VERSION ""

NS_ :

BS_:

BU_: ECU

BO_ 1706 frame_1706: 8 Vector__XXX
 SG_ checksum_57_8 : 63|8@0+ (1,0) [0|255] ""  ECU
 SG_ sig_2_29 : 2|29@1+ (1e-12,0) [0|0.00053687091] "W"  ECU
 SG_ sig_0_2 : 0|2@1+ (1,0) [0|3] ""  ECU
 SG_ sig_42_14 : 42|14@1- (1,0) [-8192|8190] ""  ECU
 SG_ sig_34_6 : 34|6@1+ (1,0) [0|62] ""  ECU
 SG_ sig_33_2 : 33|2@0- (1,0) [-2|1] ""  ECU

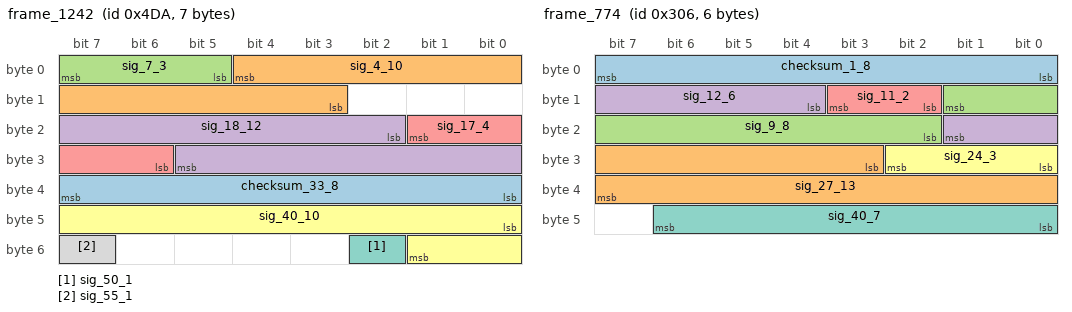
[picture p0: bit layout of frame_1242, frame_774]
BO_ 1242 frame_1242: 7 Vector__XXX
 SG_ checksum_33_8 : 39|8@0+ (1,0) [0|255] ""  ECU
 SG_ sig_4_10 : 4|10@0- (1e-06,0) [-0.000512|0.00051] "V"  ECU
 SG_ sig_7_3 : 7|3@0- (1,0) [-4|2] ""  ECU
 SG_ sig_18_12 : 18|12@1+ (0.001,-3.1622776602) [-3.1622776602|0.93172233983] "s"  ECU
 SG_ sig_17_4 : 17|4@0- (1,0) [-8|6] ""  ECU
 SG_ sig_40_10 : 40|10@1+ (0.0001,0.031622776602) [0.031622776602|0.1338227766] "W"  ECU
 SG_ sig_50_1 : 50|1@1+ (1,0) [0|1] ""  ECU
 SG_ sig_55_1 : 55|1@0+ (1,0) [0|1] ""  ECU

BO_ 774 frame_774: 6 Vector__XXX
 SG_ checksum_1_8 : 7|8@0+ (1,0) [0|255] ""  ECU
 SG_ sig_27_13 : 27|13@1- (0.0001,0) [-0.4096|0.4094] "W"  ECU
 SG_ sig_9_8 : 9|8@0- (1e-05,0) [-0.00128|0.00126] "kWh"  ECU
 SG_ sig_12_6 : 12|6@1- (1,0) [-32|30] ""  ECU
 SG_ sig_11_2 : 11|2@0- (1,0) [-2|1] ""  ECU
 SG_ sig_24_3 : 24|3@1+ (1,0) [0|6] ""  ECU
 SG_ sig_40_7 : 40|7@1- (0.01,0.31622776602) [-0.32377223398|0.93622776602] "s"  ECU

BO_ 2147485692 frame_x2044: 4 ECU
 SG_ checksum_17_8 : 16|8@1+ (1,0) [0|255] "" Vector__XXX
 SG_ sig_0_14 : 0|14@1- (1e-08,3.1622776602e-05) [-5.0297223398e-05|0.0001135227766] "m/s^2" Vector__XXX
 SG_ sig_15_2 : 15|2@0- (1,0) [-2|1] "" Vector__XXX
 SG_ sig_31_2 : 31|2@0- (1,0) [-2|1] "" Vector__XXX
 SG_ sig_24_1 : 24|1@1+ (1,0) [0|1] "" Vector__XXX

BO_ 1907 frame_1907: 7 Vector__XXX
 SG_ checksum_1_8 : 7|8@0+ (1,0) [0|255] ""  ECU
 SG_ sig_31_1 : 31|1@0+ (1,0) [0|1] ""  ECU
 SG_ sig_15_16 : 15|16@0- (0.001,-31.622776602) [-64.390776602|1.1432233983] "m/s^2"  ECU
 SG_ sig_25_24 : 25|24@0- (0.0001,316.22776602) [-522.63303398|1155.088366] "W"  ECU
 SG_ sig_30_5 : 30|5@0- (1,0) [-16|14] ""  ECU

BO_ 594 frame_594: 7 Vector__XXX
 SG_ checksum_33_8 : 39|8@0+ (1,0) [0|255] ""  ECU
 SG_ sig_5_25 : 5|25@1+ (0.001,0) [0|33554.43] "s"  ECU
 SG_ sig_1_4 : 1|4@1- (1,3.1622776602) [-4.8377223398|9.1622776602] "A"  ECU
 SG_ sig_0_1 : 0|1@0+ (1,0) [0|1] ""  ECU
 SG_ sig_30_2 : 30|2@1- (1,0) [-2|1] ""  ECU
 SG_ sig_47_16 : 47|16@0- (1e-07,0) [-0.0032768|0.0032766] "m/s^2"  ECU

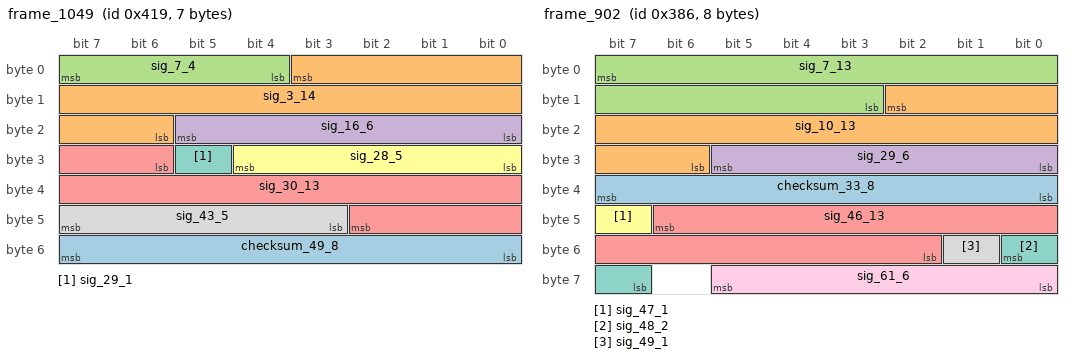
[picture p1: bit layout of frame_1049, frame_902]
BO_ 1049 frame_1049: 7 ECU
 SG_ checksum_49_8 : 48|8@1+ (1,0) [0|255] "" Vector__XXX
 SG_ sig_3_14 : 3|14@0+ (0.001,3.1622776602) [3.1622776602|19.54427766] "A" Vector__XXX
 SG_ sig_7_4 : 7|4@0+ (1,0) [0|14] "" Vector__XXX
 SG_ sig_16_6 : 16|6@1- (1,0) [-32|30] "" Vector__XXX
 SG_ sig_30_13 : 30|13@1+ (1,3162.2776602) [3162.2776602|11352.27766] "s" Vector__XXX
 SG_ sig_28_5 : 28|5@0- (1,0) [-16|14] "" Vector__XXX
 SG_ sig_29_1 : 29|1@0+ (1,0) [0|1] "" Vector__XXX
 SG_ sig_43_5 : 43|5@1+ (100,0) [0|3000] "km/h" Vector__XXX

BO_ 1207 frame_1207: 7 Vector__XXX
 SG_ checksum_1_8 : 0|8@1+ (1,0) [0|255] ""  ECU
 SG_ sig_19_31 : 19|31@1- (1e-10,0) [-0.1073741824|0.1073741822] "V"  ECU
 SG_ sig_9_10 : 9|10@1- (100,0) [-51200|51000] "km/h"  ECU
 SG_ sig_8_1 : 8|1@0+ (1,0) [0|1] ""  ECU
 SG_ sig_55_4 : 55|4@0- (1e-06,-3.1622776602e-06) [-1.116227766e-05|2.8377223398e-06] "km/h"  ECU

BO_ 902 frame_902: 8 Vector__XXX
 SG_ checksum_33_8 : 39|8@0+ (1,0) [0|255] ""  ECU
 SG_ sig_10_13 : 10|13@0- (1e-09,3.1622776602e-06) [-9.3372233983e-07|7.2562776602e-06] "W"  ECU
 SG_ sig_7_13 : 7|13@0- (1,0) [-4096|4094] ""  ECU
 SG_ sig_29_6 : 29|6@0+ (0.1,3.1622776602) [3.1622776602|9.3622776602] "kWh"  ECU
 SG_ sig_46_13 : 46|13@0+ (0.1,0) [0|819] "m/s^2"  ECU
 SG_ sig_47_1 : 47|1@0+ (1,0) [0|1] ""  ECU
 SG_ sig_48_2 : 48|2@0+ (1,0) [0|3] ""  ECU
 SG_ sig_49_1 : 49|1@0+ (1,0) [0|1] ""  ECU
 SG_ sig_61_6 : 61|6@0+ (1,0) [0|62] ""  ECU

BO_ 1834 frame_1834: 6 ECU
 SG_ checksum_17_8 : 16|8@1+ (1,0) [0|255] "" Vector__XXX
 SG_ sig_7_16 : 7|16@0+ (1e-09,0) [0|6.5534e-05] "m/s^2" Vector__XXX
 SG_ sig_28_20 : 28|20@0+ (1e-07,-0.031622776602) [-0.031622776602|0.073234623398] "W" Vector__XXX
 SG_ sig_29_3 : 29|3@1+ (1,0) [0|6] "" Vector__XXX
 SG_ sig_40_1 : 40|1@1+ (1,0) [0|1] "" Vector__XXX

BO_ 609 frame_609: 5 Vector__XXX
 SG_ checksum_1_8 : 7|8@0+ (1,0) [0|255] ""  ECU
 SG_ sig_22_5 : 22|5@0- (1,0) [-16|14] ""  ECU
 SG_ sig_8_8 : 8|8@1- (10,0) [-1280|1260] "km/h"  ECU
 SG_ sig_16_2 : 16|2@1+ (1,0) [0|3] ""  ECU
 SG_ sig_23_16 : 23|16@1+ (1,0) [0|65534] ""  ECU

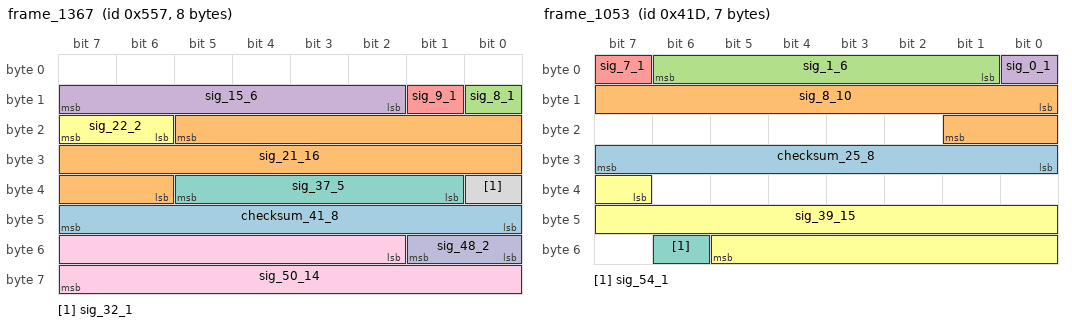
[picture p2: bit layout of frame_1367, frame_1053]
BO_ 1367 frame_1367: 8 Vector__XXX
 SG_ checksum_41_8 : 40|8@1+ (1,0) [0|255] ""  ECU
 SG_ sig_21_16 : 21|16@0- (0.0001,0) [-3.2768|3.2766] "W"  ECU
 SG_ sig_8_1 : 8|1@1+ (1,0) [0|1] ""  ECU
 SG_ sig_15_6 : 15|6@0- (100,3162.2776602) [-37.722339832|6162.2776602] "s"  ECU
 SG_ sig_9_1 : 9|1@0+ (1,0) [0|1] ""  ECU
 SG_ sig_22_2 : 22|2@1+ (1,0) [0|3] ""  ECU
 SG_ sig_37_5 : 37|5@0+ (1,0) [0|30] ""  ECU
 SG_ sig_32_1 : 32|1@1+ (1,0) [0|1] ""  ECU
 SG_ sig_50_14 : 50|14@1+ (0.01,0) [0|163.82] "m/s^2"  ECU
 SG_ sig_48_2 : 48|2@1- (1,0) [-2|1] ""  ECU

BO_ 1053 frame_1053: 7 ECU
 SG_ checksum_25_8 : 24|8@1+ (1,0) [0|255] "" Vector__XXX
 SG_ sig_8_10 : 8|10@1- (1,0) [-512|510] "" Vector__XXX
 SG_ sig_1_6 : 1|6@1- (1,0) [-32|30] "" Vector__XXX
 SG_ sig_0_1 : 0|1@1+ (1,0) [0|1] "" Vector__XXX
 SG_ sig_7_1 : 7|1@1+ (1,0) [0|1] "" Vector__XXX
 SG_ sig_39_15 : 39|15@1+ (0.0001,0) [0|3.2766] "m/s^2" Vector__XXX
 SG_ sig_54_1 : 54|1@1+ (1,0) [0|1] "" Vector__XXX

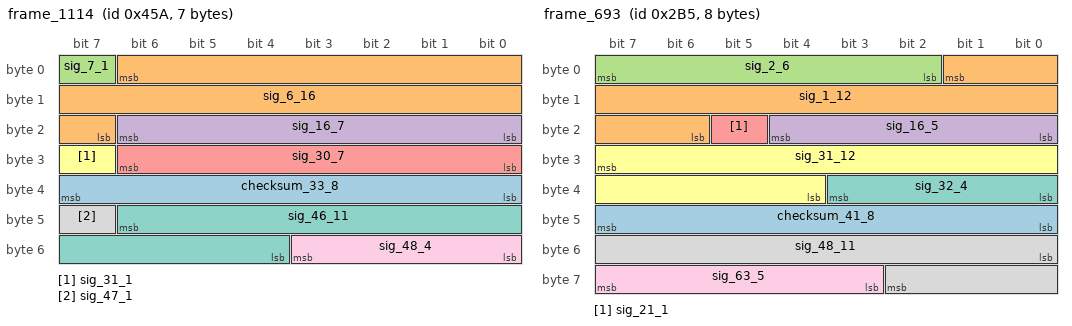
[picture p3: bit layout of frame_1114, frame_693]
BO_ 1114 frame_1114: 7 Vector__XXX
 SG_ checksum_33_8 : 32|8@1+ (1,0) [0|255] ""  ECU
 SG_ sig_6_16 : 6|16@0- (1e-07,0) [-0.0032768|0.0032766] "s"  ECU
 SG_ sig_7_1 : 7|1@1+ (1,0) [0|1] ""  ECU
 SG_ sig_16_7 : 16|7@1- (0.001,0) [-0.064|0.062] "kWh"  ECU
 SG_ sig_30_7 : 30|7@0+ (0.0001,0) [0|0.0126] "V"  ECU
 SG_ sig_31_1 : 31|1@1+ (1,0) [0|1] ""  ECU
 SG_ sig_46_11 : 46|11@0+ (1e-08,0) [0|2.046e-05] "m/s^2"  ECU
 SG_ sig_47_1 : 47|1@0+ (1,0) [0|1] ""  ECU
 SG_ sig_48_4 : 48|4@1+ (10000,-31622.776602) [-31622.776602|108377.2234] "V"  ECU

BO_ 693 frame_693: 8 ECU
 SG_ checksum_41_8 : 40|8@1+ (1,0) [0|255] "" Vector__XXX
 SG_ sig_1_12 : 1|12@0- (1e-06,0) [-0.002048|0.002046] "V" Vector__XXX
 SG_ sig_2_6 : 2|6@1- (1e-06,-3.1622776602e-05) [-6.3622776602e-05|-1.6227766017e-06] "m/s^2" Vector__XXX
 SG_ sig_16_5 : 16|5@1- (1,0) [-16|14] "" Vector__XXX
 SG_ sig_21_1 : 21|1@0+ (1,0) [0|1] "" Vector__XXX
 SG_ sig_31_12 : 31|12@0+ (0.1,0) [0|409.4] "V" Vector__XXX
 SG_ sig_32_4 : 32|4@1- (1000,0) [-8000|6000] "kWh" Vector__XXX
 SG_ sig_48_11 : 48|11@1- (1,0) [-1024|1022] "" Vector__XXX
 SG_ sig_63_5 : 63|5@0+ (0.01,0) [0|0.3] "m/s^2" Vector__XXX

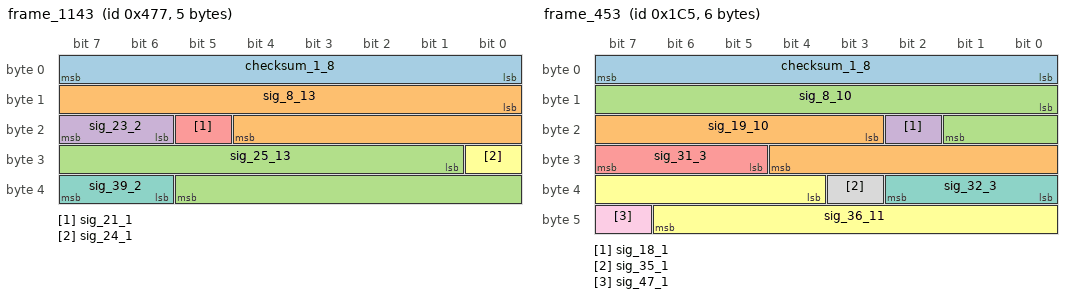
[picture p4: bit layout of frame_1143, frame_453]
BO_ 1143 frame_1143: 5 ECU
 SG_ checksum_1_8 : 7|8@0+ (1,0) [0|255] "" Vector__XXX
 SG_ sig_8_13 : 8|13@1+ (0.0001,0.31622776602) [0.31622776602|1.135227766] "A" Vector__XXX
 SG_ sig_25_13 : 25|13@1- (1e-09,0) [-4.096e-06|4.094e-06] "m/s^2" Vector__XXX
 SG_ sig_23_2 : 23|2@0- (1,0) [-2|1] "" Vector__XXX
 SG_ sig_21_1 : 21|1@0+ (1,0) [0|1] "" Vector__XXX
 SG_ sig_24_1 : 24|1@1+ (1,0) [0|1] "" Vector__XXX
 SG_ sig_39_2 : 39|2@0- (1,0) [-2|1] "" Vector__XXX

BO_ 667 frame_667: 7 Vector__XXX
 SG_ checksum_1_8 : 0|8@1+ (1,0) [0|255] ""  ECU
 SG_ sig_22_35 : 22|35@0+ (1e-07,3162.2776602) [3162.2776602|6598.2514968] "A"  ECU
 SG_ sig_9_6 : 9|6@1+ (0.1,3.1622776602) [3.1622776602|9.3622776602] "s"  ECU
 SG_ sig_48_3 : 48|3@1- (1,0) [-4|2] ""  ECU

BO_ 453 frame_453: 6 ECU
 SG_ checksum_1_8 : 7|8@0+ (1,0) [0|255] "" Vector__XXX
 SG_ sig_19_10 : 19|10@1+ (1e-07,-3.1622776602e-05) [-3.1622776602e-05|7.0577223398e-05] "A" Vector__XXX
 SG_ sig_8_10 : 8|10@1+ (1,0) [0|1022] "" Vector__XXX
 SG_ sig_18_1 : 18|1@1+ (1,0) [0|1] "" Vector__XXX
 SG_ sig_31_3 : 31|3@0- (1,0) [-4|2] "" Vector__XXX
 SG_ sig_36_11 : 36|11@1+ (1e-05,-0.0031622776602) [-0.0031622776602|0.01729772234] "m/s^2" Vector__XXX
 SG_ sig_32_3 : 32|3@1- (1,0) [-4|2] "" Vector__XXX
 SG_ sig_35_1 : 35|1@0+ (1,0) [0|1] "" Vector__XXX
 SG_ sig_47_1 : 47|1@0+ (1,0) [0|1] "" Vector__XXX

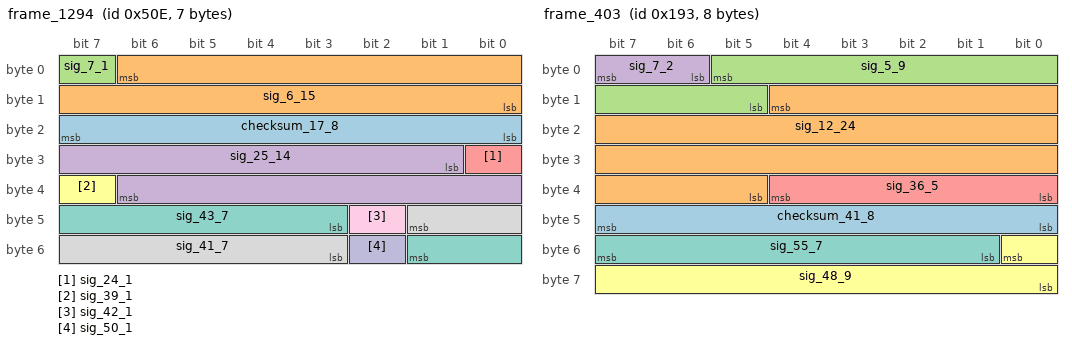
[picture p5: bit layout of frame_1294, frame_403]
BO_ 1294 frame_1294: 7 Vector__XXX
 SG_ checksum_17_8 : 23|8@0+ (1,0) [0|255] ""  ECU
 SG_ sig_6_15 : 6|15@0- (0.01,0) [-163.84|163.82] "V"  ECU
 SG_ sig_7_1 : 7|1@0+ (1,0) [0|1] ""  ECU
 SG_ sig_25_14 : 25|14@1+ (0.01,0) [0|163.82] "kWh"  ECU
 SG_ sig_24_1 : 24|1@1+ (1,0) [0|1] ""  ECU
 SG_ sig_39_1 : 39|1@0+ (1,0) [0|1] ""  ECU
 SG_ sig_43_7 : 43|7@1- (0.0001,-0.0031622776602) [-0.0095622776602|0.0030377223398] "m/s^2"  ECU
 SG_ sig_41_7 : 41|7@0- (1e-06,0) [-6.4e-05|6.2e-05] "m/s^2"  ECU
 SG_ sig_42_1 : 42|1@0+ (1,0) [0|1] ""  ECU
 SG_ sig_50_1 : 50|1@0+ (1,0) [0|1] ""  ECU

BO_ 403 frame_403: 8 ECU
 SG_ checksum_41_8 : 47|8@0+ (1,0) [0|255] "" Vector__XXX
 SG_ sig_12_24 : 12|24@0+ (1e-12,-3.1622776602e-06) [-3.1622776602e-06|1.361493634e-05] "s" Vector__XXX
 SG_ sig_5_9 : 5|9@0- (1e-07,0) [-2.56e-05|2.54e-05] "m/s^2" Vector__XXX
 SG_ sig_7_2 : 7|2@0+ (1,0) [0|3] "" Vector__XXX
 SG_ sig_36_5 : 36|5@0- (1,0) [-16|14] "" Vector__XXX
 SG_ sig_48_9 : 48|9@0+ (0.0001,-0.031622776602) [-0.031622776602|0.019377223398] "W" Vector__XXX
 SG_ sig_55_7 : 55|7@0+ (1,-31.622776602) [-31.622776602|94.377223398] "V" Vector__XXX

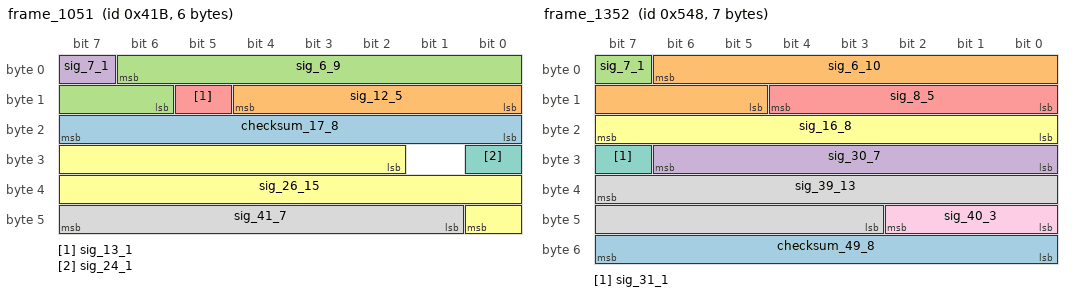
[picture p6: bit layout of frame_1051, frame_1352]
BO_ 1051 frame_1051: 6 Vector__XXX
 SG_ checksum_17_8 : 23|8@0+ (1,0) [0|255] ""  ECU
 SG_ sig_12_5 : 12|5@0+ (1,0) [0|30] "km/h"  ECU
 SG_ sig_6_9 : 6|9@0- (1e-07,0) [-2.56e-05|2.54e-05] "m/s^2"  ECU
 SG_ sig_7_1 : 7|1@0+ (1,0) [0|1] ""  ECU
 SG_ sig_13_1 : 13|1@0+ (1,0) [0|1] ""  ECU
 SG_ sig_26_15 : 26|15@1- (1,0) [-16384|16382] ""  ECU
 SG_ sig_24_1 : 24|1@0+ (1,0) [0|1] ""  ECU
 SG_ sig_41_7 : 41|7@1+ (0.0001,0.0031622776602) [0.0031622776602|0.01576227766] "A"  ECU

BO_ 1352 frame_1352: 7 Vector__XXX
 SG_ checksum_49_8 : 48|8@1+ (1,0) [0|255] ""  ECU
 SG_ sig_6_10 : 6|10@0+ (1e-06,0) [0|0.001022] "W"  ECU
 SG_ sig_7_1 : 7|1@0+ (1,0) [0|1] ""  ECU
 SG_ sig_30_7 : 30|7@0+ (1,0) [0|126] ""  ECU
 SG_ sig_8_5 : 8|5@1+ (1,0) [0|30] "kWh"  ECU
 SG_ sig_16_8 : 16|8@1+ (0.01,0.31622776602) [0.31622776602|2.856227766] "m/s^2"  ECU
 SG_ sig_31_1 : 31|1@0+ (1,0) [0|1] ""  ECU
 SG_ sig_39_13 : 39|13@0- (1e-07,-0.00031622776602) [-0.00072582776602|9.3172233983e-05] "km/h"  ECU
 SG_ sig_40_3 : 40|3@1- (1,0) [-4|2] ""  ECU

BO_ 1140 frame_1140: 7 Vector__XXX
 SG_ checksum_33_8 : 32|8@1+ (1,0) [0|255] ""  ECU
 SG_ sig_16_14 : 16|14@1- (0.0001,0.31622776602) [-0.50297223398|1.135227766] "kWh"  ECU
 SG_ sig_3_11 : 3|11@1- (1,0) [-1024|1022] ""  ECU
 SG_ sig_0_3 : 0|3@0+ (1,0) [0|6] ""  ECU
 SG_ sig_40_16 : 40|16@1- (1e-07,0) [-0.0032768|0.0032766] "A"  ECU

BO_ 652 frame_652: 6 Vector__XXX
 SG_ checksum_1_8 : 7|8@0+ (1,0) [0|255] ""  ECU
 SG_ sig_10_2 : 10|2@1+ (1,0) [0|3] ""  ECU
 SG_ sig_9_2 : 9|2@0+ (1,0) [0|3] ""  ECU
 SG_ sig_34_11 : 34|11@1+ (1e-05,0.0031622776602) [0.0031622776602|0.02362227766] "W"  ECU
 SG_ sig_32_2 : 32|2@1- (1,0) [-2|1] ""  ECU
 SG_ sig_47_3 : 47|3@0- (1,0) [-4|2] ""  ECU

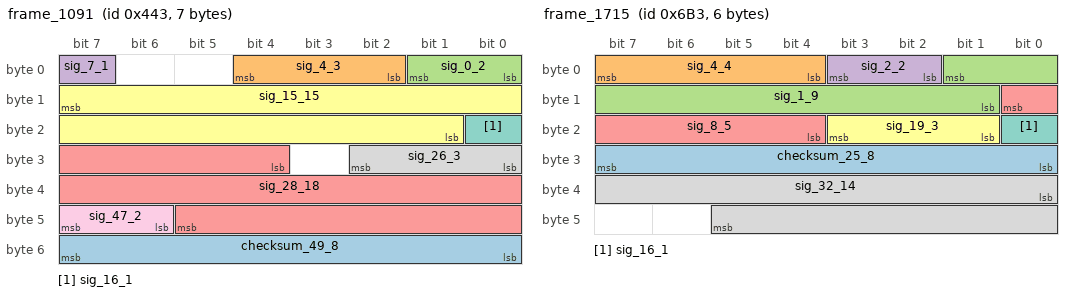
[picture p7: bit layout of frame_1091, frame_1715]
BO_ 1091 frame_1091: 7 Vector__XXX
 SG_ checksum_49_8 : 55|8@0+ (1,0) [0|255] ""  ECU
 SG_ sig_4_3 : 4|3@0+ (1,0) [0|6] ""  ECU
 SG_ sig_0_2 : 0|2@1+ (1,0) [0|3] ""  ECU
 SG_ sig_7_1 : 7|1@0+ (1,0) [0|1] ""  ECU
 SG_ sig_28_18 : 28|18@1- (1e-08,0.00031622776602) [-0.00099449223398|0.001626927766] "V"  ECU
 SG_ sig_15_15 : 15|15@0- (1,0) [-16384|16382] ""  ECU
 SG_ sig_16_1 : 16|1@0+ (1,0) [0|1] ""  ECU
 SG_ sig_26_3 : 26|3@0- (1,0) [-4|2] ""  ECU
 SG_ sig_47_2 : 47|2@0- (1,0) [-2|1] ""  ECU

BO_ 1715 frame_1715: 6 Vector__XXX
 SG_ checksum_25_8 : 31|8@0+ (1,0) [0|255] ""  ECU
 SG_ sig_4_4 : 4|4@1- (10000,-31622.776602) [-111622.7766|28377.223398] "kWh"  ECU
 SG_ sig_1_9 : 1|9@0+ (1,0) [0|510] ""  ECU
 SG_ sig_2_2 : 2|2@1+ (1,0) [0|3] ""  ECU
 SG_ sig_8_5 : 8|5@0+ (1e-05,0.00031622776602) [0.00031622776602|0.00061622776602] "km/h"  ECU
 SG_ sig_19_3 : 19|3@0- (1,0) [-4|2] ""  ECU
 SG_ sig_16_1 : 16|1@1+ (1,0) [0|1] ""  ECU
 SG_ sig_32_14 : 32|14@1+ (1,-3162.2776602) [-3162.2776602|13219.72234] "V"  ECU

BO_ 766 frame_766: 7 ECU
 SG_ checksum_9_8 : 8|8@1+ (1,0) [0|255] "" Vector__XXX
 SG_ sig_0_1 : 0|1@1+ (1,0) [0|1] "" Vector__XXX
 SG_ sig_17_39 : 17|39@1+ (1e-07,-31622.776602) [-31622.776602|23352.804787] "kWh" Vector__XXX
 SG_ sig_16_1 : 16|1@1+ (1,0) [0|1] "" Vector__XXX

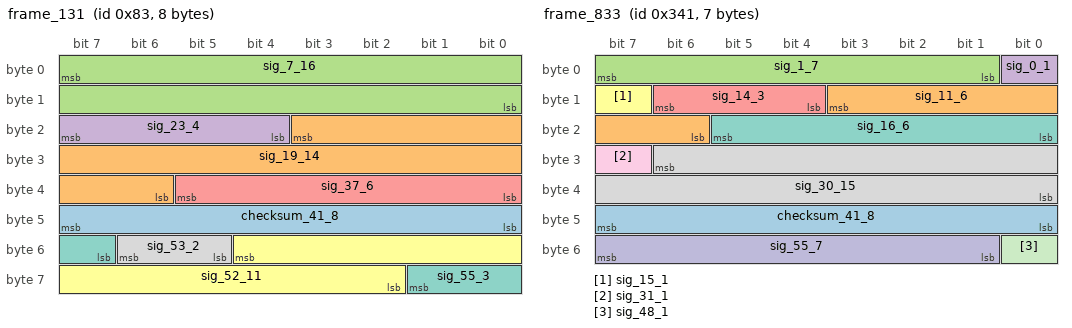
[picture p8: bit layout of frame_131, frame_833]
BO_ 131 frame_131: 8 Vector__XXX
 SG_ checksum_41_8 : 40|8@1+ (1,0) [0|255] ""  ECU
 SG_ sig_19_14 : 19|14@0+ (1e-09,0) [0|1.6382e-05] "V"  ECU
 SG_ sig_7_16 : 7|16@0+ (1,0) [0|65534] ""  ECU
 SG_ sig_23_4 : 23|4@0- (0.01,0.031622776602) [-0.048377223398|0.091622776602] "m/s^2"  ECU
 SG_ sig_37_6 : 37|6@0- (0.1,0) [-3.2|3] "W"  ECU
 SG_ sig_52_11 : 52|11@0+ (1,0) [0|2046] ""  ECU
 SG_ sig_55_3 : 55|3@1- (1,0) [-4|2] ""  ECU
 SG_ sig_53_2 : 53|2@1- (1,0) [-2|1] ""  ECU

BO_ 1271 frame_1271: 6 ECU
 SG_ checksum_41_8 : 40|8@1+ (1,0) [0|255] "" Vector__XXX
 SG_ sig_5_37 : 5|37@0- (1e-10,-3.1622776602) [-10.034225334|3.7096700132] "km/h" Vector__XXX
 SG_ sig_7_2 : 7|2@0- (1,0) [-2|1] "" Vector__XXX
 SG_ sig_32_1 : 32|1@0+ (1,0) [0|1] "" Vector__XXX

BO_ 332 frame_332: 5 ECU
 SG_ checksum_17_8 : 23|8@0+ (1,0) [0|255] "" Vector__XXX
 SG_ sig_3_7 : 3|7@1+ (1e-07,-3.1622776602e-06) [-3.1622776602e-06|9.4377223398e-06] "km/h" Vector__XXX
 SG_ sig_1_8 : 1|8@0- (1e-05,-0.00031622776602) [-0.001596227766|0.00094377223398] "W" Vector__XXX
 SG_ sig_2_1 : 2|1@0+ (1,0) [0|1] "" Vector__XXX
 SG_ sig_31_16 : 31|16@0- (1,0) [-32768|32766] "" Vector__XXX

BO_ 602 frame_602: 7 ECU
 SG_ checksum_1_8 : 0|8@1+ (1,0) [0|255] "" Vector__XXX
 SG_ sig_40_15 : 40|15@1+ (1e-05,0) [0|0.32766] "V" Vector__XXX
 SG_ sig_9_12 : 9|12@1+ (0.01,0) [0|40.94] "km/h" Vector__XXX
 SG_ sig_8_1 : 8|1@1+ (1,0) [0|1] "" Vector__XXX
 SG_ sig_21_19 : 21|19@1+ (1e-11,0) [0|5.24286e-06] "kWh" Vector__XXX
 SG_ sig_55_1 : 55|1@1+ (1,0) [0|1] "" Vector__XXX

BO_ 833 frame_833: 7 Vector__XXX
 SG_ checksum_41_8 : 47|8@0+ (1,0) [0|255] ""  ECU
 SG_ sig_11_6 : 11|6@0- (1,0) [-32|30] ""  ECU
 SG_ sig_1_7 : 1|7@1+ (1,0) [0|126] ""  ECU
 SG_ sig_0_1 : 0|1@1+ (1,0) [0|1] ""  ECU
 SG_ sig_14_3 : 14|3@0- (1,0) [-4|2] ""  ECU
 SG_ sig_15_1 : 15|1@0+ (1,0) [0|1] ""  ECU
 SG_ sig_16_6 : 16|6@1- (1,0) [-32|30] ""  ECU
 SG_ sig_30_15 : 30|15@0+ (0.001,31.622776602) [31.622776602|64.388776602] "m/s^2"  ECU
 SG_ sig_31_1 : 31|1@0+ (1,0) [0|1] ""  ECU
 SG_ sig_55_7 : 55|7@0- (1,0) [-64|62] ""  ECU
 SG_ sig_48_1 : 48|1@0+ (1,0) [0|1] ""  ECU

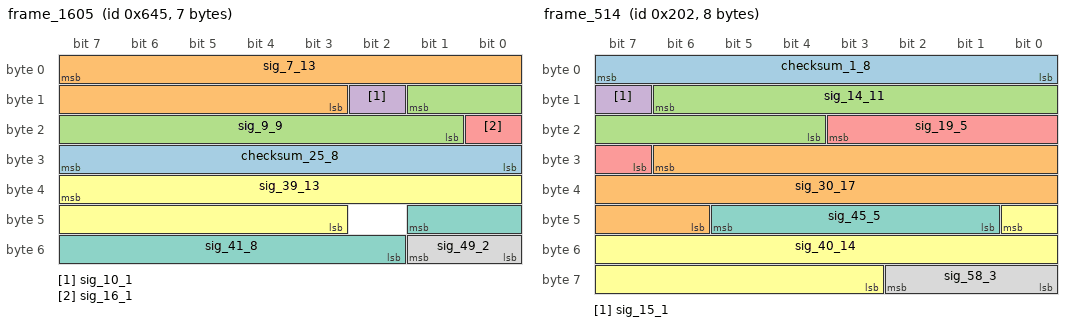
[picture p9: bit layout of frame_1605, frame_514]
BO_ 1605 frame_1605: 7 ECU
 SG_ checksum_25_8 : 31|8@0+ (1,0) [0|255] "" Vector__XXX
 SG_ sig_7_13 : 7|13@0+ (1,0) [0|8190] "" Vector__XXX
 SG_ sig_9_9 : 9|9@0+ (1,0) [0|510] "" Vector__XXX
 SG_ sig_10_1 : 10|1@0+ (1,0) [0|1] "" Vector__XXX
 SG_ sig_16_1 : 16|1@0+ (1,0) [0|1] "" Vector__XXX
 SG_ sig_39_13 : 39|13@0- (1e-08,0) [-4.096e-05|4.094e-05] "W" Vector__XXX
 SG_ sig_41_8 : 41|8@0- (1,0) [-128|126] "" Vector__XXX
 SG_ sig_49_2 : 49|2@0+ (1,0) [0|3] "" Vector__XXX

BO_ 514 frame_514: 8 Vector__XXX
 SG_ checksum_1_8 : 7|8@0+ (1,0) [0|255] ""  ECU
 SG_ sig_30_17 : 30|17@0- (1,0) [-65536|65534] ""  ECU
 SG_ sig_14_11 : 14|11@0- (1,0) [-1024|1022] ""  ECU
 SG_ sig_15_1 : 15|1@0+ (1,0) [0|1] ""  ECU
 SG_ sig_19_5 : 19|5@0+ (1000,-31622.776602) [-31622.776602|-1622.7766017] "m/s^2"  ECU
 SG_ sig_40_14 : 40|14@0+ (10,31622.776602) [31622.776602|195442.7766] "m/s^2"  ECU
 SG_ sig_45_5 : 45|5@0- (0.01,0) [-0.16|0.14] "V"  ECU
 SG_ sig_58_3 : 58|3@0+ (1,0) [0|6] ""  ECU

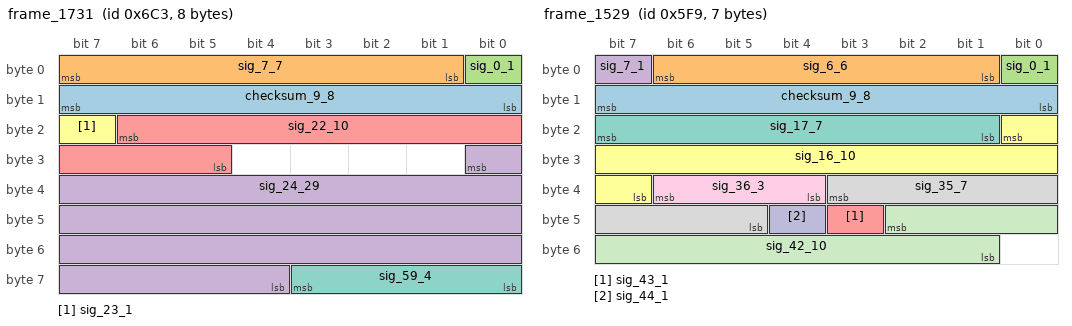
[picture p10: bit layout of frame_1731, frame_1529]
BO_ 1731 frame_1731: 8 ECU
 SG_ checksum_9_8 : 15|8@0+ (1,0) [0|255] "" Vector__XXX
 SG_ sig_7_7 : 7|7@0+ (1e-06,-3.1622776602e-05) [-3.1622776602e-05|9.4377223398e-05] "V" Vector__XXX
 SG_ sig_0_1 : 0|1@0+ (1,0) [0|1] "" Vector__XXX
 SG_ sig_24_29 : 24|29@0- (1e-14,-3.1622776602e-06) [-5.8466322202e-06|-4.7792312017e-07] "s" Vector__XXX
 SG_ sig_22_10 : 22|10@0- (1,0) [-512|510] "" Vector__XXX
 SG_ sig_23_1 : 23|1@0+ (1,0) [0|1] "" Vector__XXX
 SG_ sig_59_4 : 59|4@0+ (0.1,0) [0|1.4] "V" Vector__XXX

BO_ 1529 frame_1529: 7 ECU
 SG_ checksum_9_8 : 15|8@0+ (1,0) [0|255] "" Vector__XXX
 SG_ sig_6_6 : 6|6@0- (1,0) [-32|30] "" Vector__XXX
 SG_ sig_0_1 : 0|1@1+ (1,0) [0|1] "" Vector__XXX
 SG_ sig_7_1 : 7|1@1+ (1,0) [0|1] "" Vector__XXX
 SG_ sig_43_1 : 43|1@0+ (1,0) [0|1] "" Vector__XXX
 SG_ sig_16_10 : 16|10@0+ (0.1,31.622776602) [31.622776602|133.8227766] "V" Vector__XXX
 SG_ sig_17_7 : 17|7@1+ (1,0) [0|126] "" Vector__XXX
 SG_ sig_35_7 : 35|7@0+ (1e-05,-0.00031622776602) [-0.00031622776602|0.00094377223398] "km/h" Vector__XXX
 SG_ sig_36_3 : 36|3@1- (1,0) [-4|2] "" Vector__XXX
 SG_ sig_44_1 : 44|1@0+ (1,0) [0|1] "" Vector__XXX
 SG_ sig_42_10 : 42|10@0+ (1e-07,0) [0|0.0001022] "W" Vector__XXX

BO_ 417 frame_417: 6 Vector__XXX
 SG_ checksum_9_8 : 15|8@0+ (1,0) [0|255] ""  ECU
 SG_ sig_7_8 : 7|8@0+ (0.1,-3.1622776602) [-3.1622776602|22.23772234] "kWh"  ECU
 SG_ sig_16_14 : 16|14@0- (0.1,316.22776602) [-502.97223398|1135.227766] "km/h"  ECU
 SG_ sig_21_5 : 21|5@0+ (0.0001,0) [0|0.003] "V"  ECU
 SG_ sig_23_2 : 23|2@0- (1,0) [-2|1] ""  ECU
 SG_ sig_34_9 : 34|9@0+ (1,0) [0|510] ""  ECU
 SG_ sig_41_2 : 41|2@0+ (1,0) [0|3] ""  ECU

BO_ 808 frame_808: 6 ECU
 SG_ checksum_17_8 : 16|8@1+ (1,0) [0|255] "" Vector__XXX
 SG_ sig_2_11 : 2|11@1- (1,0) [-1024|1022] "" Vector__XXX
 SG_ sig_0_2 : 0|2@1+ (1,0) [0|3] "" Vector__XXX
 SG_ sig_28_15 : 28|15@1- (0.001,31.622776602) [15.238776602|48.004776602] "m/s^2" Vector__XXX
 SG_ sig_24_3 : 24|3@1- (1,0) [-4|2] "" Vector__XXX
 SG_ sig_27_1 : 27|1@1+ (1,0) [0|1] "" Vector__XXX
 SG_ sig_43_5 : 43|5@1+ (1,0) [0|30] "" Vector__XXX

BO_ 1181 frame_1181: 6 ECU
 SG_ checksum_1_8 : 0|8@1+ (1,0) [0|255] "" Vector__XXX
 SG_ sig_10_19 : 10|19@0- (1e-08,-0.0031622776602) [-0.0057837176602|-0.00054085766017] "W" Vector__XXX
 SG_ sig_32_13 : 32|13@1+ (1,0) [0|8190] "" Vector__XXX
 SG_ sig_47_3 : 47|3@0+ (1,0) [0|6] "" Vector__XXX

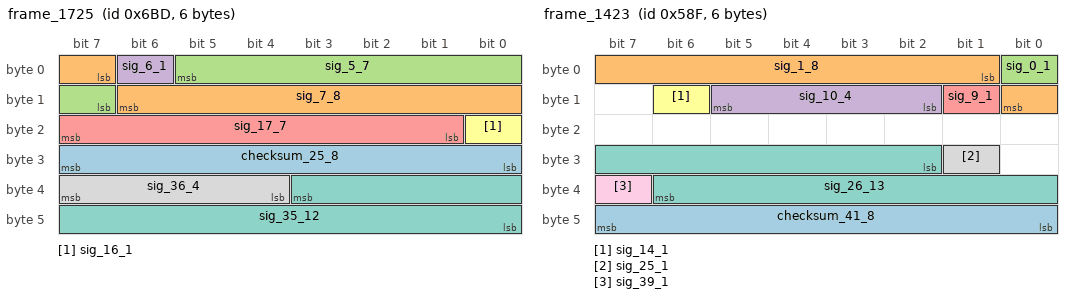
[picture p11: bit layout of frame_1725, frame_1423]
BO_ 1725 frame_1725: 6 ECU
 SG_ checksum_25_8 : 24|8@1+ (1,0) [0|255] "" Vector__XXX
 SG_ sig_7_8 : 7|8@1+ (1000,-31622.776602) [-31622.776602|222377.2234] "km/h" Vector__XXX
 SG_ sig_5_7 : 5|7@0+ (0.0001,-0.0031622776602) [-0.0031622776602|0.0094377223398] "A" Vector__XXX
 SG_ sig_6_1 : 6|1@0+ (1,0) [0|1] "" Vector__XXX
 SG_ sig_17_7 : 17|7@1+ (1e-07,0) [0|1.26e-05] "s" Vector__XXX
 SG_ sig_16_1 : 16|1@0+ (1,0) [0|1] "" Vector__XXX
 SG_ sig_35_12 : 35|12@0- (10,0) [-20480|20460] "V" Vector__XXX
 SG_ sig_36_4 : 36|4@1- (100,-316.22776602) [-1116.227766|283.77223398] "A" Vector__XXX

BO_ 208 frame_208: 6 ECU
 SG_ checksum_9_8 : 8|8@1+ (1,0) [0|255] "" Vector__XXX
 SG_ sig_7_8 : 7|8@0- (0.01,0) [-1.28|1.26] "s" Vector__XXX
 SG_ sig_24_13 : 24|13@1- (0.001,0) [-4.096|4.094] "W" Vector__XXX
 SG_ sig_39_2 : 39|2@0+ (1,0) [0|3] "" Vector__XXX
 SG_ sig_47_8 : 47|8@0- (100,0) [-12800|12600] "s" Vector__XXX

BO_ 1246 frame_1246: 5 Vector__XXX
 SG_ checksum_9_8 : 15|8@0+ (1,0) [0|255] ""  ECU
 SG_ sig_7_8 : 7|8@0+ (0.001,0.031622776602) [0.031622776602|0.2856227766] "m/s^2"  ECU
 SG_ sig_24_15 : 24|15@1- (1,0) [-16384|16382] ""  ECU
 SG_ sig_22_5 : 22|5@0- (1,31.622776602) [15.622776602|45.622776602] "W"  ECU
 SG_ sig_17_2 : 17|2@0- (1,0) [-2|1] ""  ECU

BO_ 1423 frame_1423: 6 Vector__XXX
 SG_ checksum_41_8 : 40|8@1+ (1,0) [0|255] ""  ECU
 SG_ sig_1_8 : 1|8@1+ (1,0) [0|254] ""  ECU
 SG_ sig_0_1 : 0|1@1+ (1,0) [0|1] ""  ECU
 SG_ sig_10_4 : 10|4@1- (1e-06,3.1622776602e-06) [-4.8377223398e-06|9.1622776602e-06] "V"  ECU
 SG_ sig_9_1 : 9|1@1+ (1,0) [0|1] ""  ECU
 SG_ sig_14_1 : 14|1@1+ (1,0) [0|1] ""  ECU
 SG_ sig_26_13 : 26|13@1- (10,31622.776602) [-9337.2233983|72562.776602] "s"  ECU
 SG_ sig_25_1 : 25|1@1+ (1,0) [0|1] ""  ECU
 SG_ sig_39_1 : 39|1@1+ (1,0) [0|1] ""  ECU

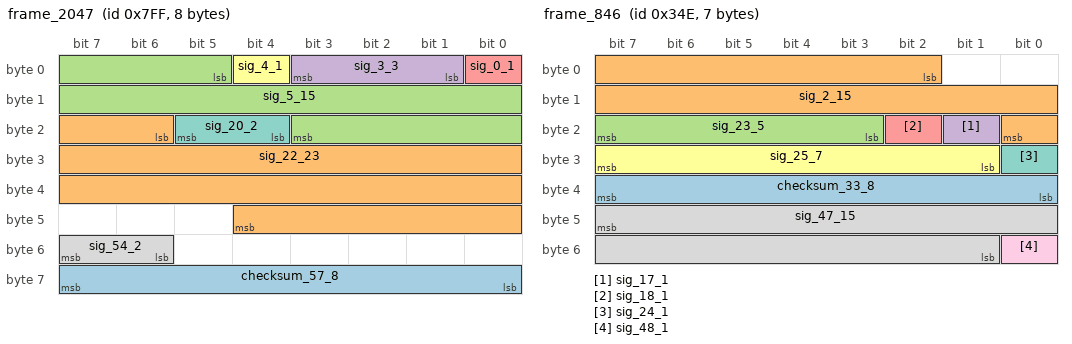
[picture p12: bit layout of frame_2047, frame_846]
BO_ 2047 frame_2047: 8 ECU
 SG_ checksum_57_8 : 56|8@1+ (1,0) [0|255] "" Vector__XXX
 SG_ sig_22_23 : 22|23@1- (1e-08,-0.031622776602) [-0.073565816602|0.010320243398] "m/s^2" Vector__XXX
 SG_ sig_5_15 : 5|15@1- (1e-07,0.0031622776602) [0.0015238776602|0.0048004776602] "km/h" Vector__XXX
 SG_ sig_3_3 : 3|3@0- (1,0) [-4|2] "" Vector__XXX
 SG_ sig_0_1 : 0|1@1+ (1,0) [0|1] "" Vector__XXX
 SG_ sig_4_1 : 4|1@1+ (1,0) [0|1] "" Vector__XXX
 SG_ sig_20_2 : 20|2@1+ (1,0) [0|3] "" Vector__XXX
 SG_ sig_54_2 : 54|2@1+ (1,0) [0|3] "" Vector__XXX

BO_ 846 frame_846: 7 Vector__XXX
 SG_ checksum_33_8 : 32|8@1+ (1,0) [0|255] ""  ECU
 SG_ sig_2_15 : 2|15@1+ (1,0) [0|32766] ""  ECU
 SG_ sig_23_5 : 23|5@0- (0.001,0.031622776602) [0.015622776602|0.045622776602] "A"  ECU
 SG_ sig_17_1 : 17|1@0+ (1,0) [0|1] ""  ECU
 SG_ sig_18_1 : 18|1@0+ (1,0) [0|1] ""  ECU
 SG_ sig_25_7 : 25|7@1+ (1,0) [0|126] ""  ECU
 SG_ sig_24_1 : 24|1@1+ (1,0) [0|1] ""  ECU
 SG_ sig_47_15 : 47|15@0- (1e-08,-0.00031622776602) [-0.00048006776602|-0.00015240776602] "m/s^2"  ECU
 SG_ sig_48_1 : 48|1@0+ (1,0) [0|1] ""  ECU

BO_ 1764 frame_1764: 7 Vector__XXX
 SG_ checksum_33_8 : 39|8@0+ (1,0) [0|255] ""  ECU
 SG_ sig_21_14 : 21|14@0- (1e-06,-0.0031622776602) [-0.01135427766|0.0050277223398] "kWh"  ECU
 SG_ sig_7_16 : 7|16@0- (1,0) [-32768|32766] ""  ECU
 SG_ sig_23_2 : 23|2@0+ (1,0) [0|3] ""  ECU
 SG_ sig_47_13 : 47|13@0- (1,0) [-4096|4094] ""  ECU
 SG_ sig_50_2 : 50|2@0+ (1,0) [0|3] ""  ECU
 SG_ sig_48_1 : 48|1@0+ (1,0) [0|1] ""  ECU

BO_ 1412 frame_1412: 5 Vector__XXX
 SG_ checksum_1_8 : 0|8@1+ (1,0) [0|255] ""  ECU
 SG_ sig_10_8 : 10|8@1- (1e-05,0) [-0.00128|0.00126] "A"  ECU
 SG_ sig_8_2 : 8|2@1- (1,0) [-2|1] ""  ECU
 SG_ sig_23_6 : 23|6@0+ (1e-05,0) [0|0.00062] "s"  ECU
 SG_ sig_27_8 : 27|8@1- (0.001,-0.031622776602) [-0.1596227766|0.094377223398] "kWh"  ECU
 SG_ sig_25_2 : 25|2@1+ (1,0) [0|3] ""  ECU
 SG_ sig_36_2 : 36|2@0- (1,0) [-2|1] ""  ECU

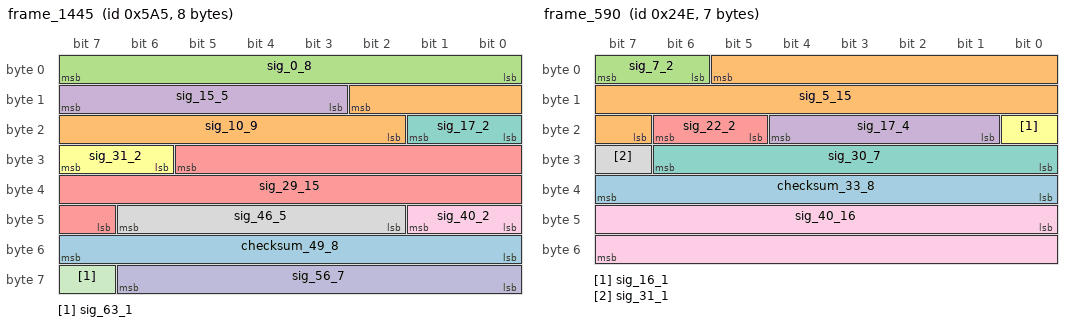
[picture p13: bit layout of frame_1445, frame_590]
BO_ 1445 frame_1445: 8 Vector__XXX
 SG_ checksum_49_8 : 48|8@1+ (1,0) [0|255] ""  ECU
 SG_ sig_10_9 : 10|9@0+ (1,0) [0|510] ""  ECU
 SG_ sig_0_8 : 0|8@1- (1e-07,0) [-1.28e-05|1.26e-05] "s"  ECU
 SG_ sig_15_5 : 15|5@0- (1000,0) [-16000|14000] "W"  ECU
 SG_ sig_29_15 : 29|15@0- (1e-07,0) [-0.0016384|0.0016382] "m/s^2"  ECU
 SG_ sig_31_2 : 31|2@0+ (1,0) [0|3] ""  ECU
 SG_ sig_17_2 : 17|2@0+ (1,0) [0|3] ""  ECU
 SG_ sig_46_5 : 46|5@0+ (1,0) [0|30] ""  ECU
 SG_ sig_40_2 : 40|2@1- (1,0) [-2|1] ""  ECU
 SG_ sig_56_7 : 56|7@1+ (1000,-31622.776602) [-31622.776602|94377.223398] "km/h"  ECU
 SG_ sig_63_1 : 63|1@1+ (1,0) [0|1] ""  ECU

BO_ 590 frame_590: 7 ECU
 SG_ checksum_33_8 : 39|8@0+ (1,0) [0|255] "" Vector__XXX
 SG_ sig_5_15 : 5|15@0+ (1,0) [0|32766] "" Vector__XXX
 SG_ sig_7_2 : 7|2@0+ (1,0) [0|3] "" Vector__XXX
 SG_ sig_17_4 : 17|4@1- (1000,-3162.2776602) [-11162.27766|2837.7223398] "m/s^2" Vector__XXX
 SG_ sig_22_2 : 22|2@0+ (1,0) [0|3] "" Vector__XXX
 SG_ sig_16_1 : 16|1@1+ (1,0) [0|1] "" Vector__XXX
 SG_ sig_30_7 : 30|7@0- (100,-3162.2776602) [-9562.2776602|3037.7223398] "A" Vector__XXX
 SG_ sig_31_1 : 31|1@0+ (1,0) [0|1] "" Vector__XXX
 SG_ sig_40_16 : 40|16@1- (0.1,3162.2776602) [-114.52233983|6438.8776602] "m/s^2" Vector__XXX

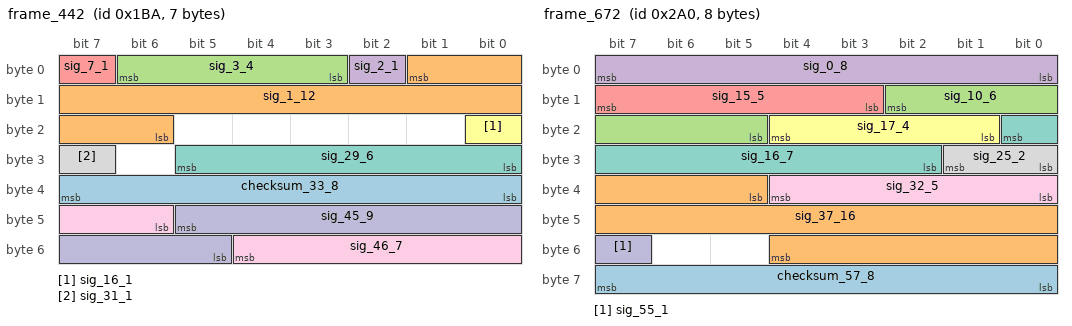
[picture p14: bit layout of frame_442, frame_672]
BO_ 442 frame_442: 7 Vector__XXX
 SG_ checksum_33_8 : 32|8@1+ (1,0) [0|255] ""  ECU
 SG_ sig_1_12 : 1|12@0+ (1,0) [0|4094] ""  ECU
 SG_ sig_3_4 : 3|4@1+ (1,0) [0|14] ""  ECU
 SG_ sig_2_1 : 2|1@1+ (1,0) [0|1] ""  ECU
 SG_ sig_7_1 : 7|1@1+ (1,0) [0|1] ""  ECU
 SG_ sig_16_1 : 16|1@1+ (1,0) [0|1] ""  ECU
 SG_ sig_29_6 : 29|6@0+ (100,0) [0|6200] "s"  ECU
 SG_ sig_31_1 : 31|1@1+ (1,0) [0|1] ""  ECU
 SG_ sig_46_7 : 46|7@1+ (0.1,3.1622776602) [3.1622776602|15.76227766] "W"  ECU
 SG_ sig_45_9 : 45|9@0- (1,0) [-256|254] ""  ECU

BO_ 672 frame_672: 8 Vector__XXX
 SG_ checksum_57_8 : 56|8@1+ (1,0) [0|255] ""  ECU
 SG_ sig_37_16 : 37|16@1- (1,0) [-32768|32766] ""  ECU
 SG_ sig_10_6 : 10|6@0- (10,316.22776602) [-3.7722339832|616.22776602] "m/s^2"  ECU
 SG_ sig_0_8 : 0|8@1- (0.1,-3.1622776602) [-15.96227766|9.4377223398] "s"  ECU
 SG_ sig_15_5 : 15|5@0+ (100,3162.2776602) [3162.2776602|6162.2776602] "A"  ECU
 SG_ sig_17_4 : 17|4@1- (1,0) [-8|6] ""  ECU
 SG_ sig_16_7 : 16|7@0+ (1,0) [0|126] ""  ECU
 SG_ sig_25_2 : 25|2@0- (1,0) [-2|1] ""  ECU
 SG_ sig_32_5 : 32|5@1+ (1,0) [0|30] ""  ECU
 SG_ sig_55_1 : 55|1@1+ (1,0) [0|1] ""  ECU

BO_ 1419 frame_1419: 6 ECU
 SG_ checksum_25_8 : 31|8@0+ (1,0) [0|255] "" Vector__XXX
 SG_ sig_8_8 : 8|8@1+ (1,0) [0|254] "" Vector__XXX
 SG_ sig_0_7 : 0|7@1- (1,0) [-64|62] "" Vector__XXX
 SG_ sig_7_1 : 7|1@1+ (1,0) [0|1] "" Vector__XXX
 SG_ sig_23_7 : 23|7@0+ (0.0001,0.0031622776602) [0.0031622776602|0.01576227766] "km/h" Vector__XXX
 SG_ sig_16_1 : 16|1@0+ (1,0) [0|1] "" Vector__XXX
 SG_ sig_32_4 : 32|4@1+ (1e-06,0) [0|1.4e-05] "V" Vector__XXX

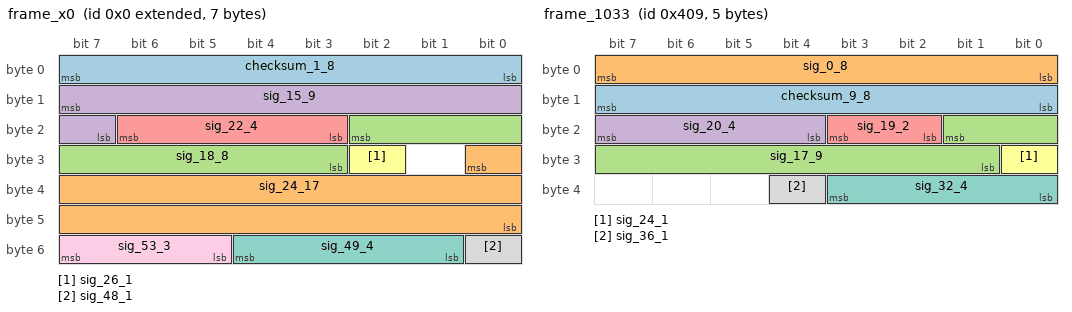
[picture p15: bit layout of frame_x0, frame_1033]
BO_ 2147483648 frame_x0: 7 ECU
 SG_ checksum_1_8 : 0|8@1+ (1,0) [0|255] "" Vector__XXX
 SG_ sig_24_17 : 24|17@0- (1e-05,0) [-0.65536|0.65534] "A" Vector__XXX
 SG_ sig_18_8 : 18|8@0+ (0.0001,0) [0|0.0254] "kWh" Vector__XXX
 SG_ sig_15_9 : 15|9@0+ (1,316.22776602) [316.22776602|826.22776602] "V" Vector__XXX
 SG_ sig_22_4 : 22|4@0+ (1,0) [0|14] "" Vector__XXX
 SG_ sig_26_1 : 26|1@0+ (1,0) [0|1] "" Vector__XXX
 SG_ sig_49_4 : 49|4@1- (1,0) [-8|6] "" Vector__XXX
 SG_ sig_48_1 : 48|1@1+ (1,0) [0|1] "" Vector__XXX
 SG_ sig_53_3 : 53|3@1- (1,0) [-4|2] "" Vector__XXX

BO_ 1630 frame_1630: 7 ECU
 SG_ checksum_49_8 : 48|8@1+ (1,0) [0|255] "" Vector__XXX
 SG_ sig_40_7 : 40|7@1+ (1,0) [0|126] "" Vector__XXX
 SG_ sig_6_15 : 6|15@0+ (0.01,316.22776602) [316.22776602|643.88776602] "s" Vector__XXX
 SG_ sig_7_1 : 7|1@1+ (1,0) [0|1] "" Vector__XXX
 SG_ sig_16_14 : 16|14@1- (1,0) [-8192|8190] "" Vector__XXX
 SG_ sig_47_1 : 47|1@0+ (1,0) [0|1] "" Vector__XXX

BO_ 718 frame_718: 7 Vector__XXX
 SG_ checksum_17_8 : 23|8@0+ (1,0) [0|255] ""  ECU
 SG_ sig_7_10 : 7|10@0+ (0.1,-31.622776602) [-31.622776602|70.577223398] "s"  ECU
 SG_ sig_10_4 : 10|4@1- (1,0) [-8|6] ""  ECU
 SG_ sig_32_17 : 32|17@0+ (1,0) [0|131070] ""  ECU
 SG_ sig_24_8 : 24|8@1+ (1,0) [0|254] ""  ECU
 SG_ sig_33_6 : 33|6@1- (0.1,-3.1622776602) [-6.3622776602|-0.16227766017] "A"  ECU

BO_ 1042 frame_1042: 7 Vector__XXX
 SG_ checksum_1_8 : 0|8@1+ (1,0) [0|255] ""  ECU
 SG_ sig_10_21 : 10|21@1+ (1e-07,-0.031622776602) [-0.031622776602|0.1780922234] "m/s^2"  ECU
 SG_ sig_8_2 : 8|2@1+ (1,0) [0|3] ""  ECU
 SG_ sig_35_12 : 35|12@1- (1,0) [-2048|2046] ""  ECU
 SG_ sig_33_2 : 33|2@1+ (1,0) [0|3] ""  ECU
 SG_ sig_47_7 : 47|7@1+ (1e-06,3.1622776602e-05) [3.1622776602e-05|0.0001576227766] "kWh"  ECU
 SG_ sig_54_2 : 54|2@1- (1,0) [-2|1] ""  ECU

BO_ 2147485695 frame_x2047: 8 Vector__XXX
 SG_ checksum_33_8 : 39|8@0+ (1,0) [0|255] ""  ECU
 SG_ sig_7_17 : 7|17@1+ (1e-08,0) [0|0.0013107] "V"  ECU
 SG_ sig_0_7 : 0|7@1+ (0.1,-3.1622776602) [-3.1622776602|9.4377223398] "A"  ECU
 SG_ sig_24_8 : 24|8@1+ (10,316.22776602) [316.22776602|2856.227766] "kWh"  ECU
 SG_ sig_40_15 : 40|15@1+ (1e-05,0) [0|0.32766] "m/s^2"  ECU
 SG_ sig_55_1 : 55|1@0+ (1,0) [0|1] ""  ECU
 SG_ sig_56_8 : 56|8@1- (0.01,0) [-1.28|1.26] "kWh"  ECU

BO_ 1473 frame_1473: 7 Vector__XXX
 SG_ checksum_17_8 : 23|8@0+ (1,0) [0|255] ""  ECU
 SG_ sig_3_9 : 3|9@0- (1e-07,0) [-2.56e-05|2.54e-05] "m/s^2"  ECU
 SG_ sig_4_7 : 4|7@1+ (1,0) [0|126] ""  ECU
 SG_ sig_24_16 : 24|16@1- (0.0001,3.1622776602) [-0.11452233983|6.4388776602] "s"  ECU
 SG_ sig_47_16 : 47|16@0- (1e-09,3.1622776602e-05) [-1.1452233983e-06|6.4388776602e-05] "kWh"  ECU

BO_ 1033 frame_1033: 5 ECU
 SG_ checksum_9_8 : 15|8@0+ (1,0) [0|255] "" Vector__XXX
 SG_ sig_0_8 : 0|8@1- (0.1,-3.1622776602) [-15.96227766|9.4377223398] "V" Vector__XXX
 SG_ sig_17_9 : 17|9@0- (1,0) [-256|254] "" Vector__XXX
 SG_ sig_20_4 : 20|4@1- (0.001,0.0031622776602) [-0.0048377223398|0.0091622776602] "V" Vector__XXX
 SG_ sig_19_2 : 19|2@0- (1,0) [-2|1] "" Vector__XXX
 SG_ sig_24_1 : 24|1@1+ (1,0) [0|1] "" Vector__XXX
 SG_ sig_32_4 : 32|4@1+ (1,0) [0|14] "" Vector__XXX
 SG_ sig_36_1 : 36|1@1+ (1,0) [0|1] "" Vector__XXX

BO_ 803 frame_803: 4 ECU
 SG_ checksum_17_8 : 16|8@1+ (1,0) [0|255] "" Vector__XXX
 SG_ sig_1_10 : 1|10@1+ (1,316.22776602) [316.22776602|1338.227766] "km/h" Vector__XXX
 SG_ sig_0_6 : 0|6@0- (0.001,0.031622776602) [-0.00037722339832|0.061622776602] "kWh" Vector__XXX
 SG_ sig_24_8 : 24|8@1- (1,0) [-128|126] "" Vector__XXX

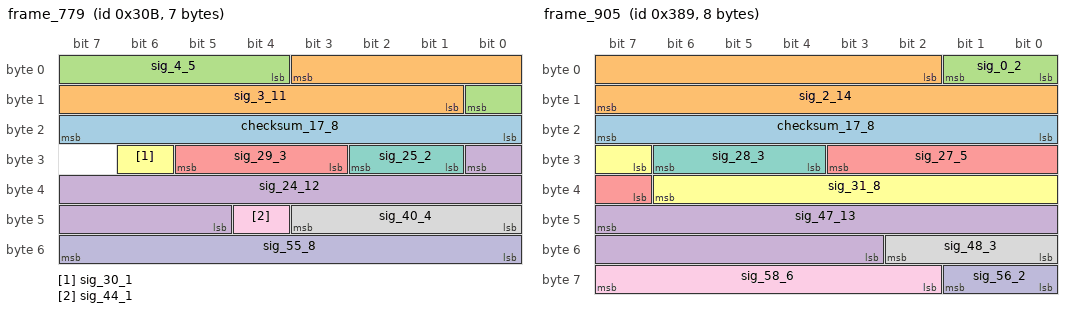
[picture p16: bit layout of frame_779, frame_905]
BO_ 779 frame_779: 7 Vector__XXX
 SG_ checksum_17_8 : 23|8@0+ (1,0) [0|255] ""  ECU
 SG_ sig_3_11 : 3|11@0- (0.001,-0.31622776602) [-1.340227766|0.70577223398] "s"  ECU
 SG_ sig_4_5 : 4|5@1- (1e-07,-3.1622776602e-06) [-4.7622776602e-06|-1.7622776602e-06] "kWh"  ECU
 SG_ sig_24_12 : 24|12@0+ (1,0) [0|4094] ""  ECU
 SG_ sig_29_3 : 29|3@0+ (1,0) [0|6] ""  ECU
 SG_ sig_30_1 : 30|1@0+ (1,0) [0|1] ""  ECU
 SG_ sig_25_2 : 25|2@1+ (1,0) [0|3] ""  ECU
 SG_ sig_40_4 : 40|4@1+ (100,0) [0|1400] "m/s^2"  ECU
 SG_ sig_44_1 : 44|1@1+ (1,0) [0|1] ""  ECU
 SG_ sig_55_8 : 55|8@0+ (100,-3162.2776602) [-3162.2776602|22237.72234] "A"  ECU

BO_ 106 frame_106: 5 ECU
 SG_ checksum_17_8 : 16|8@1+ (1,0) [0|255] "" Vector__XXX
 SG_ sig_7_11 : 7|11@0+ (0.1,31.622776602) [31.622776602|236.2227766] "A" Vector__XXX
 SG_ sig_8_5 : 8|5@1- (0.0001,0) [-0.0016|0.0014] "W" Vector__XXX
 SG_ sig_29_14 : 29|14@0+ (10,-31622.776602) [-31622.776602|132197.2234] "W" Vector__XXX
 SG_ sig_30_2 : 30|2@1- (1,0) [-2|1] "" Vector__XXX

BO_ 905 frame_905: 8 ECU
 SG_ checksum_17_8 : 16|8@1+ (1,0) [0|255] "" Vector__XXX
 SG_ sig_2_14 : 2|14@1+ (1e-08,-3.1622776602e-05) [-3.1622776602e-05|0.0001321972234] "s" Vector__XXX
 SG_ sig_0_2 : 0|2@1+ (1,0) [0|3] "" Vector__XXX
 SG_ sig_47_13 : 47|13@0- (1,3162.2776602) [-933.72233983|7256.2776602] "A" Vector__XXX
 SG_ sig_27_5 : 27|5@0+ (1,0) [0|30] "" Vector__XXX
 SG_ sig_31_8 : 31|8@1+ (1,0) [0|254] "" Vector__XXX
 SG_ sig_28_3 : 28|3@1+ (1,0) [0|6] "" Vector__XXX
 SG_ sig_48_3 : 48|3@1+ (1,0) [0|6] "" Vector__XXX
 SG_ sig_58_6 : 58|6@1- (0.01,0) [-0.32|0.3] "W" Vector__XXX
 SG_ sig_56_2 : 56|2@1+ (1,0) [0|3] "" Vector__XXX

BO_ 877 frame_877: 4 Vector__XXX
 SG_ checksum_9_8 : 8|8@1+ (1,0) [0|255] ""  ECU
 SG_ sig_7_7 : 7|7@0- (100,3162.2776602) [-3237.7223398|9362.2776602] "kWh"  ECU
 SG_ sig_0_1 : 0|1@0+ (1,0) [0|1] ""  ECU
 SG_ sig_20_7 : 20|7@0+ (1e-06,3.1622776602e-05) [3.1622776602e-05|0.0001576227766] "A"  ECU
 SG_ sig_21_9 : 21|9@1- (0.1,0) [-25.6|25.4] "m/s^2"  ECU

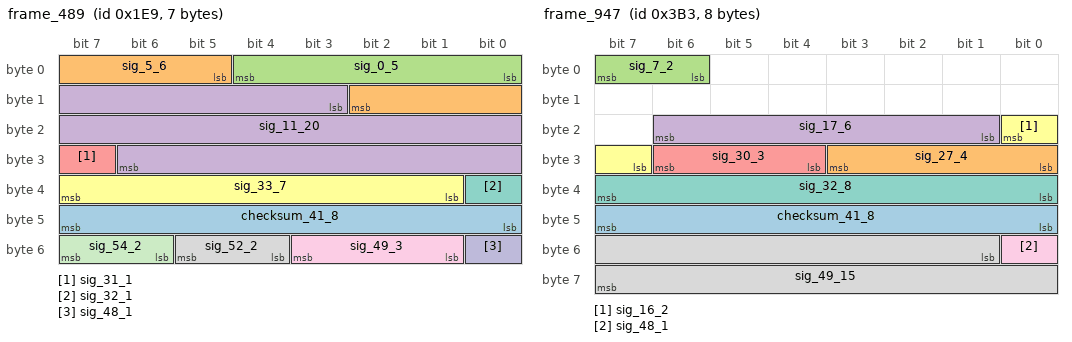
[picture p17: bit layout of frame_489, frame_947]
BO_ 489 frame_489: 7 Vector__XXX
 SG_ checksum_41_8 : 40|8@1+ (1,0) [0|255] ""  ECU
 SG_ sig_5_6 : 5|6@1- (1e-06,0) [-3.2e-05|3e-05] "kWh"  ECU
 SG_ sig_0_5 : 0|5@1- (0.0001,0) [-0.0016|0.0014] "V"  ECU
 SG_ sig_11_20 : 11|20@1+ (0.1,31622.776602) [31622.776602|136480.1766] "m/s^2"  ECU
 SG_ sig_31_1 : 31|1@0+ (1,0) [0|1] ""  ECU
 SG_ sig_33_7 : 33|7@1- (1000,31622.776602) [-32377.223398|93622.776602] "A"  ECU
 SG_ sig_32_1 : 32|1@1+ (1,0) [0|1] ""  ECU
 SG_ sig_52_2 : 52|2@1- (1,0) [-2|1] ""  ECU
 SG_ sig_49_3 : 49|3@1+ (1,0) [0|6] ""  ECU
 SG_ sig_48_1 : 48|1@1+ (1,0) [0|1] ""  ECU
 SG_ sig_54_2 : 54|2@1+ (1,0) [0|3] ""  ECU

BO_ 1758 frame_1758: 5 Vector__XXX
 SG_ checksum_25_8 : 24|8@1+ (1,0) [0|255] ""  ECU
 SG_ sig_6_16 : 6|16@0- (1,0) [-32768|32766] ""  ECU
 SG_ sig_7_1 : 7|1@0+ (1,0) [0|1] ""  ECU
 SG_ sig_16_7 : 16|7@1- (1000,-31622.776602) [-95622.776602|30377.223398] "W"  ECU
 SG_ sig_39_8 : 39|8@0- (1,31.622776602) [-96.377223398|157.6227766] "V"  ECU

BO_ 0 frame_0: 7 ECU
 SG_ checksum_1_8 : 0|8@1+ (1,0) [0|255] "" Vector__XXX
 SG_ sig_11_13 : 11|13@1+ (1e-07,-0.00031622776602) [-0.00031622776602|0.00050277223398] "W" Vector__XXX
 SG_ sig_9_2 : 9|2@1+ (1,0) [0|3] "" Vector__XXX
 SG_ sig_8_1 : 8|1@0+ (1,0) [0|1] "" Vector__XXX
 SG_ sig_30_24 : 30|24@0+ (1e-11,3.1622776602e-05) [3.1622776602e-05|0.0001993949166] "m/s^2" Vector__XXX
 SG_ sig_31_1 : 31|1@1+ (1,0) [0|1] "" Vector__XXX
 SG_ sig_54_7 : 54|7@0- (1,-31.622776602) [-95.622776602|30.377223398] "km/h" Vector__XXX

BO_ 1324 frame_1324: 2 Vector__XXX
 SG_ checksum_9_8 : 15|8@0+ (1,0) [0|255] ""  ECU
 SG_ sig_7_5 : 7|5@0- (0.001,0) [-0.016|0.014] "km/h"  ECU
 SG_ sig_2_3 : 2|3@0- (1,0) [-4|2] ""  ECU

BO_ 1885 frame_1885: 4 ECU
 SG_ checksum_1_8 : 7|8@0+ (1,0) [0|255] "" Vector__XXX
 SG_ sig_13_13 : 13|13@0- (1,0) [-4096|4094] "" Vector__XXX
 SG_ sig_15_2 : 15|2@0- (1,0) [-2|1] "" Vector__XXX
 SG_ sig_31_8 : 31|8@0+ (1,0) [0|254] "" Vector__XXX
 SG_ sig_16_1 : 16|1@0+ (1,0) [0|1] "" Vector__XXX

BO_ 1415 frame_1415: 5 ECU
 SG_ checksum_33_8 : 32|8@1+ (1,0) [0|255] "" Vector__XXX
 SG_ sig_9_12 : 9|12@0- (1,0) [-2048|2046] "" Vector__XXX
 SG_ sig_0_4 : 0|4@1+ (1000,0) [0|14000] "s" Vector__XXX
 SG_ sig_11_5 : 11|5@1- (1e-05,-0.00031622776602) [-0.00047622776602|-0.00017622776602] "A" Vector__XXX
 SG_ sig_10_1 : 10|1@0+ (1,0) [0|1] "" Vector__XXX
 SG_ sig_29_5 : 29|5@0+ (100,3162.2776602) [3162.2776602|6162.2776602] "W" Vector__XXX
 SG_ sig_24_1 : 24|1@0+ (1,0) [0|1] "" Vector__XXX

BO_ 1252 frame_1252: 5 Vector__XXX
 SG_ checksum_25_8 : 31|8@0+ (1,0) [0|255] ""  ECU
 SG_ sig_2_17 : 2|17@1- (1,31622.776602) [-33913.223398|97156.776602] "m/s^2"  ECU
 SG_ sig_0_2 : 0|2@1- (1,0) [-2|1] ""  ECU
 SG_ sig_23_5 : 23|5@0- (1,0) [-16|14] ""  ECU
 SG_ sig_39_7 : 39|7@0+ (0.001,0.031622776602) [0.031622776602|0.1576227766] "m/s^2"  ECU
 SG_ sig_32_1 : 32|1@0+ (1,0) [0|1] ""  ECU

BO_ 947 frame_947: 8 Vector__XXX
 SG_ checksum_41_8 : 47|8@0+ (1,0) [0|255] ""  ECU
 SG_ sig_27_4 : 27|4@0+ (0.1,-0.31622776602) [-0.31622776602|1.083772234] "s"  ECU
 SG_ sig_7_2 : 7|2@0- (1,0) [-2|1] ""  ECU
 SG_ sig_17_6 : 17|6@1+ (0.0001,0.0031622776602) [0.0031622776602|0.0093622776602] "km/h"  ECU
 SG_ sig_30_3 : 30|3@0+ (1,0) [0|6] ""  ECU
 SG_ sig_16_2 : 16|2@0- (1,0) [-2|1] ""  ECU
 SG_ sig_32_8 : 32|8@1+ (1,0) [0|254] ""  ECU
 SG_ sig_49_15 : 49|15@1+ (1,0) [0|32766] ""  ECU
 SG_ sig_48_1 : 48|1@0+ (1,0) [0|1] ""  ECU

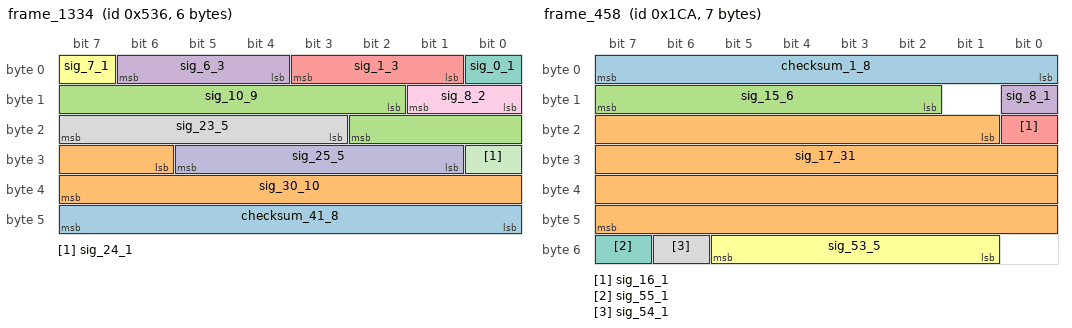
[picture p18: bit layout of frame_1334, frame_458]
BO_ 1334 frame_1334: 6 Vector__XXX
 SG_ checksum_41_8 : 47|8@0+ (1,0) [0|255] ""  ECU
 SG_ sig_30_10 : 30|10@1+ (1,316.22776602) [316.22776602|1338.227766] "V"  ECU
 SG_ sig_10_9 : 10|9@1+ (1,0) [0|510] ""  ECU
 SG_ sig_6_3 : 6|3@0+ (1,0) [0|6] ""  ECU
 SG_ sig_1_3 : 1|3@1- (1,0) [-4|2] ""  ECU
 SG_ sig_7_1 : 7|1@0+ (1,0) [0|1] ""  ECU
 SG_ sig_0_1 : 0|1@1+ (1,0) [0|1] ""  ECU
 SG_ sig_23_5 : 23|5@0- (1,0) [-16|14] ""  ECU
 SG_ sig_8_2 : 8|2@1+ (1,0) [0|3] ""  ECU
 SG_ sig_25_5 : 25|5@1+ (10,0) [0|300] "s"  ECU
 SG_ sig_24_1 : 24|1@0+ (1,0) [0|1] ""  ECU

BO_ 458 frame_458: 7 Vector__XXX
 SG_ checksum_1_8 : 0|8@1+ (1,0) [0|255] ""  ECU
 SG_ sig_17_31 : 17|31@1+ (0.0001,31622.776602) [31622.776602|246371.1412] "s"  ECU
 SG_ sig_15_6 : 15|6@0- (100,3162.2776602) [-37.722339832|6162.2776602] "kWh"  ECU
 SG_ sig_8_1 : 8|1@0+ (1,0) [0|1] ""  ECU
 SG_ sig_16_1 : 16|1@1+ (1,0) [0|1] ""  ECU
 SG_ sig_53_5 : 53|5@0+ (0.0001,0.0031622776602) [0.0031622776602|0.0061622776602] "V"  ECU
 SG_ sig_55_1 : 55|1@0+ (1,0) [0|1] ""  ECU
 SG_ sig_54_1 : 54|1@0+ (1,0) [0|1] ""  ECU

BO_ 915 frame_915: 6 ECU
 SG_ checksum_25_8 : 31|8@0+ (1,0) [0|255] "" Vector__XXX
 SG_ sig_1_12 : 1|12@1- (1e-06,0.0031622776602) [0.0011142776602|0.0052082776602] "s" Vector__XXX
 SG_ sig_0_1 : 0|1@1+ (1,0) [0|1] "" Vector__XXX
 SG_ sig_36_13 : 36|13@0+ (1e-08,3.1622776602e-05) [3.1622776602e-05|0.0001135227766] "A" Vector__XXX
 SG_ sig_39_2 : 39|2@0- (1,0) [-2|1] "" Vector__XXX
 SG_ sig_37_1 : 37|1@0+ (1,0) [0|1] "" Vector__XXX

BO_ 349 frame_349: 6 ECU
 SG_ checksum_17_8 : 23|8@0+ (1,0) [0|255] "" Vector__XXX
 SG_ sig_3_13 : 3|13@1- (1e-09,-3.1622776602e-06) [-7.2582776602e-06|9.3172233983e-07] "kWh" Vector__XXX
 SG_ sig_2_3 : 2|3@0- (1,0) [-4|2] "" Vector__XXX
 SG_ sig_28_10 : 28|10@0- (1e-06,-0.00031622776602) [-0.00082822776602|0.00019377223398] "kWh" Vector__XXX
 SG_ sig_46_7 : 46|7@0- (1,0) [-64|62] "" Vector__XXX
 SG_ sig_47_1 : 47|1@0+ (1,0) [0|1] "" Vector__XXX

BO_ 1 frame_1: 3 Vector__XXX
 SG_ checksum_1_8 : 7|8@0+ (1,0) [0|255] ""  ECU
 SG_ sig_13_13 : 13|13@0+ (1,-3162.2776602) [-3162.2776602|5027.7223398] "V"  ECU
 SG_ sig_15_2 : 15|2@0+ (1,0) [0|3] ""  ECU
 SG_ sig_16_1 : 16|1@1+ (1,0) [0|1] ""  ECU

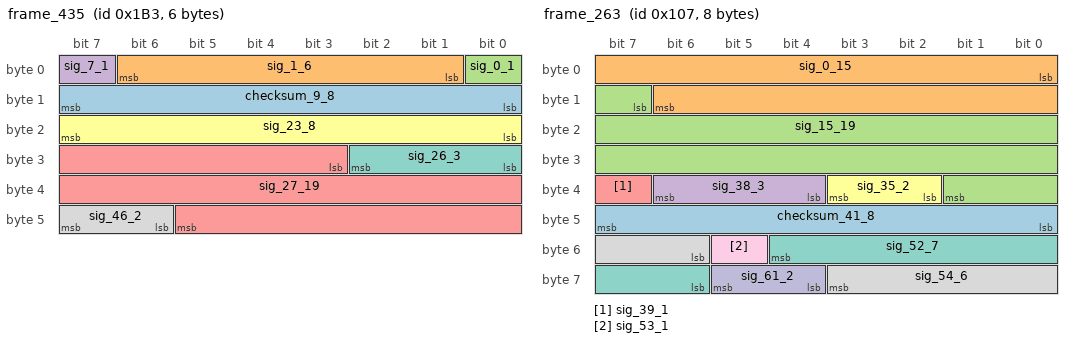
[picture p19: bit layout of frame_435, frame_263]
BO_ 435 frame_435: 6 Vector__XXX
 SG_ checksum_9_8 : 8|8@1+ (1,0) [0|255] ""  ECU
 SG_ sig_1_6 : 1|6@1- (100,-3162.2776602) [-6362.2776602|-162.27766017] "km/h"  ECU
 SG_ sig_0_1 : 0|1@1+ (1,0) [0|1] ""  ECU
 SG_ sig_7_1 : 7|1@0+ (1,0) [0|1] ""  ECU
 SG_ sig_27_19 : 27|19@1- (1e-11,0) [-2.62144e-06|2.62142e-06] "km/h"  ECU
 SG_ sig_23_8 : 23|8@0+ (100,0) [0|25400] "A"  ECU
 SG_ sig_26_3 : 26|3@0+ (1,0) [0|6] ""  ECU
 SG_ sig_46_2 : 46|2@1- (1,0) [-2|1] ""  ECU

BO_ 982 frame_982: 7 Vector__XXX
 SG_ checksum_1_8 : 7|8@0+ (1,0) [0|255] ""  ECU
 SG_ sig_13_23 : 13|23@0- (1e-11,3.1622776602e-05) [-1.0320263398e-05|7.3565796602e-05] "s"  ECU
 SG_ sig_15_2 : 15|2@0+ (1,0) [0|3] ""  ECU
 SG_ sig_37_18 : 37|18@0- (1,0) [-131072|131070] ""  ECU
 SG_ sig_38_1 : 38|1@0+ (1,0) [0|1] ""  ECU
 SG_ sig_51_3 : 51|3@0- (1,0) [-4|2] ""  ECU
 SG_ sig_48_1 : 48|1@0+ (1,0) [0|1] ""  ECU

BO_ 263 frame_263: 8 Vector__XXX
 SG_ checksum_41_8 : 40|8@1+ (1,0) [0|255] ""  ECU
 SG_ sig_0_15 : 0|15@1+ (1,0) [0|32766] ""  ECU
 SG_ sig_15_19 : 15|19@1+ (1e-10,0) [0|5.24286e-05] "W"  ECU
 SG_ sig_38_3 : 38|3@0+ (1,0) [0|6] ""  ECU
 SG_ sig_39_1 : 39|1@0+ (1,0) [0|1] ""  ECU
 SG_ sig_35_2 : 35|2@0+ (1,0) [0|3] ""  ECU
 SG_ sig_52_7 : 52|7@0- (10,0) [-640|620] "A"  ECU
 SG_ sig_54_6 : 54|6@1+ (1e-06,3.1622776602e-05) [3.1622776602e-05|9.3622776602e-05] "m/s^2"  ECU
 SG_ sig_53_1 : 53|1@1+ (1,0) [0|1] ""  ECU
 SG_ sig_61_2 : 61|2@0- (1,0) [-2|1] ""  ECU

CM_ BO_ 1706 "Randomly defined CAN frame";
CM_ SG_ 1706 checksum_57_8 "8 Bit checksum for protection of frame contents";
CM_ BO_ 1242 "Randomly defined CAN frame";
CM_ SG_ 1242 checksum_33_8 "8 Bit checksum for protection of frame contents";
CM_ BO_ 774 "Randomly defined CAN frame";
CM_ SG_ 774 checksum_1_8 "8 Bit checksum for protection of frame contents";
CM_ BO_ 2147485692 "Randomly defined CAN frame";
CM_ SG_ 2147485692 checksum_17_8 "8 Bit checksum for protection of frame contents";
CM_ BO_ 1907 "Randomly defined CAN frame";
CM_ SG_ 1907 checksum_1_8 "8 Bit checksum for protection of frame contents";
CM_ BO_ 594 "Randomly defined CAN frame";
CM_ SG_ 594 checksum_33_8 "8 Bit checksum for protection of frame contents";
CM_ BO_ 1049 "Randomly defined CAN frame";
CM_ SG_ 1049 checksum_49_8 "8 Bit checksum for protection of frame contents";
CM_ BO_ 1207 "Randomly defined CAN frame";
CM_ SG_ 1207 checksum_1_8 "8 Bit checksum for protection of frame contents";
CM_ BO_ 902 "Randomly defined CAN frame";
CM_ SG_ 902 checksum_33_8 "8 Bit checksum for protection of frame contents";
CM_ BO_ 1834 "Randomly defined CAN frame";
CM_ SG_ 1834 checksum_17_8 "8 Bit checksum for protection of frame contents";
CM_ BO_ 609 "Randomly defined CAN frame";
CM_ SG_ 609 checksum_1_8 "8 Bit checksum for protection of frame contents";
CM_ BO_ 1367 "Randomly defined CAN frame";
CM_ SG_ 1367 checksum_41_8 "8 Bit checksum for protection of frame contents";
CM_ BO_ 1053 "Randomly defined CAN frame";
CM_ SG_ 1053 checksum_25_8 "8 Bit checksum for protection of frame contents";
CM_ BO_ 1114 "Randomly defined CAN frame";
CM_ SG_ 1114 checksum_33_8 "8 Bit checksum for protection of frame contents";
CM_ BO_ 693 "Randomly defined CAN frame";
CM_ SG_ 693 checksum_41_8 "8 Bit checksum for protection of frame contents";
CM_ BO_ 1143 "Randomly defined CAN frame";
CM_ SG_ 1143 checksum_1_8 "8 Bit checksum for protection of frame contents";
CM_ BO_ 667 "Randomly defined CAN frame";
CM_ SG_ 667 checksum_1_8 "8 Bit checksum for protection of frame contents";
CM_ BO_ 453 "Randomly defined CAN frame";
CM_ SG_ 453 checksum_1_8 "8 Bit checksum for protection of frame contents";
CM_ BO_ 1294 "Randomly defined CAN frame";
CM_ SG_ 1294 checksum_17_8 "8 Bit checksum for protection of frame contents";
CM_ BO_ 403 "Randomly defined CAN frame";
CM_ SG_ 403 checksum_41_8 "8 Bit checksum for protection of frame contents";
CM_ BO_ 1051 "Randomly defined CAN frame";
CM_ SG_ 1051 checksum_17_8 "8 Bit checksum for protection of frame contents";
CM_ BO_ 1352 "Randomly defined CAN frame";
CM_ SG_ 1352 checksum_49_8 "8 Bit checksum for protection of frame contents";
CM_ BO_ 1140 "Randomly defined CAN frame";
CM_ SG_ 1140 checksum_33_8 "8 Bit checksum for protection of frame contents";
CM_ BO_ 652 "Randomly defined CAN frame";
CM_ SG_ 652 checksum_1_8 "8 Bit checksum for protection of frame contents";
CM_ BO_ 1091 "Randomly defined CAN frame";
CM_ SG_ 1091 checksum_49_8 "8 Bit checksum for protection of frame contents";
CM_ BO_ 1715 "Randomly defined CAN frame";
CM_ SG_ 1715 checksum_25_8 "8 Bit checksum for protection of frame contents";
CM_ BO_ 766 "Randomly defined CAN frame";
CM_ SG_ 766 checksum_9_8 "8 Bit checksum for protection of frame contents";
CM_ BO_ 131 "Randomly defined CAN frame";
CM_ SG_ 131 checksum_41_8 "8 Bit checksum for protection of frame contents";
CM_ BO_ 1271 "Randomly defined CAN frame";
CM_ SG_ 1271 checksum_41_8 "8 Bit checksum for protection of frame contents";
CM_ BO_ 332 "Randomly defined CAN frame";
CM_ SG_ 332 checksum_17_8 "8 Bit checksum for protection of frame contents";
CM_ BO_ 602 "Randomly defined CAN frame";
CM_ SG_ 602 checksum_1_8 "8 Bit checksum for protection of frame contents";
CM_ BO_ 833 "Randomly defined CAN frame";
CM_ SG_ 833 checksum_41_8 "8 Bit checksum for protection of frame contents";
CM_ BO_ 1605 "Randomly defined CAN frame";
CM_ SG_ 1605 checksum_25_8 "8 Bit checksum for protection of frame contents";
CM_ BO_ 514 "Randomly defined CAN frame";
CM_ SG_ 514 checksum_1_8 "8 Bit checksum for protection of frame contents";
CM_ BO_ 1731 "Randomly defined CAN frame";
CM_ SG_ 1731 checksum_9_8 "8 Bit checksum for protection of frame contents";
CM_ BO_ 1529 "Randomly defined CAN frame";
CM_ SG_ 1529 checksum_9_8 "8 Bit checksum for protection of frame contents";
CM_ BO_ 417 "Randomly defined CAN frame";
CM_ SG_ 417 checksum_9_8 "8 Bit checksum for protection of frame contents";
CM_ BO_ 808 "Randomly defined CAN frame";
CM_ SG_ 808 checksum_17_8 "8 Bit checksum for protection of frame contents";
CM_ BO_ 1181 "Randomly defined CAN frame";
CM_ SG_ 1181 checksum_1_8 "8 Bit checksum for protection of frame contents";
CM_ BO_ 1725 "Randomly defined CAN frame";
CM_ SG_ 1725 checksum_25_8 "8 Bit checksum for protection of frame contents";
CM_ BO_ 208 "Randomly defined CAN frame";
CM_ SG_ 208 checksum_9_8 "8 Bit checksum for protection of frame contents";
CM_ BO_ 1246 "Randomly defined CAN frame";
CM_ SG_ 1246 checksum_9_8 "8 Bit checksum for protection of frame contents";
CM_ BO_ 1423 "Randomly defined CAN frame";
CM_ SG_ 1423 checksum_41_8 "8 Bit checksum for protection of frame contents";
CM_ BO_ 2047 "Randomly defined CAN frame";
CM_ SG_ 2047 checksum_57_8 "8 Bit checksum for protection of frame contents";
CM_ BO_ 846 "Randomly defined CAN frame";
CM_ SG_ 846 checksum_33_8 "8 Bit checksum for protection of frame contents";
CM_ BO_ 1764 "Randomly defined CAN frame";
CM_ SG_ 1764 checksum_33_8 "8 Bit checksum for protection of frame contents";
CM_ BO_ 1412 "Randomly defined CAN frame";
CM_ SG_ 1412 checksum_1_8 "8 Bit checksum for protection of frame contents";
CM_ BO_ 1445 "Randomly defined CAN frame";
CM_ SG_ 1445 checksum_49_8 "8 Bit checksum for protection of frame contents";
CM_ BO_ 590 "Randomly defined CAN frame";
CM_ SG_ 590 checksum_33_8 "8 Bit checksum for protection of frame contents";
CM_ BO_ 442 "Randomly defined CAN frame";
CM_ SG_ 442 checksum_33_8 "8 Bit checksum for protection of frame contents";
CM_ BO_ 672 "Randomly defined CAN frame";
CM_ SG_ 672 checksum_57_8 "8 Bit checksum for protection of frame contents";
CM_ BO_ 1419 "Randomly defined CAN frame";
CM_ SG_ 1419 checksum_25_8 "8 Bit checksum for protection of frame contents";
CM_ BO_ 2147483648 "Randomly defined CAN frame";
CM_ SG_ 2147483648 checksum_1_8 "8 Bit checksum for protection of frame contents";
CM_ BO_ 1630 "Randomly defined CAN frame";
CM_ SG_ 1630 checksum_49_8 "8 Bit checksum for protection of frame contents";
CM_ BO_ 718 "Randomly defined CAN frame";
CM_ SG_ 718 checksum_17_8 "8 Bit checksum for protection of frame contents";
CM_ BO_ 1042 "Randomly defined CAN frame";
CM_ SG_ 1042 checksum_1_8 "8 Bit checksum for protection of frame contents";
CM_ BO_ 2147485695 "Randomly defined CAN frame";
CM_ SG_ 2147485695 checksum_33_8 "8 Bit checksum for protection of frame contents";
CM_ BO_ 1473 "Randomly defined CAN frame";
CM_ SG_ 1473 checksum_17_8 "8 Bit checksum for protection of frame contents";
CM_ BO_ 1033 "Randomly defined CAN frame";
CM_ SG_ 1033 checksum_9_8 "8 Bit checksum for protection of frame contents";
CM_ BO_ 803 "Randomly defined CAN frame";
CM_ SG_ 803 checksum_17_8 "8 Bit checksum for protection of frame contents";
CM_ BO_ 779 "Randomly defined CAN frame";
CM_ SG_ 779 checksum_17_8 "8 Bit checksum for protection of frame contents";
CM_ BO_ 106 "Randomly defined CAN frame";
CM_ SG_ 106 checksum_17_8 "8 Bit checksum for protection of frame contents";
CM_ BO_ 905 "Randomly defined CAN frame";
CM_ SG_ 905 checksum_17_8 "8 Bit checksum for protection of frame contents";
CM_ BO_ 877 "Randomly defined CAN frame";
CM_ SG_ 877 checksum_9_8 "8 Bit checksum for protection of frame contents";
CM_ BO_ 489 "Randomly defined CAN frame";
CM_ SG_ 489 checksum_41_8 "8 Bit checksum for protection of frame contents";
CM_ BO_ 1758 "Randomly defined CAN frame";
CM_ SG_ 1758 checksum_25_8 "8 Bit checksum for protection of frame contents";
CM_ BO_ 0 "Randomly defined CAN frame";
CM_ SG_ 0 checksum_1_8 "8 Bit checksum for protection of frame contents";
CM_ BO_ 1324 "Randomly defined CAN frame";
CM_ SG_ 1324 checksum_9_8 "8 Bit checksum for protection of frame contents";
CM_ BO_ 1885 "Randomly defined CAN frame";
CM_ SG_ 1885 checksum_1_8 "8 Bit checksum for protection of frame contents";
CM_ BO_ 1415 "Randomly defined CAN frame";
CM_ SG_ 1415 checksum_33_8 "8 Bit checksum for protection of frame contents";
CM_ BO_ 1252 "Randomly defined CAN frame";
CM_ SG_ 1252 checksum_25_8 "8 Bit checksum for protection of frame contents";
CM_ BO_ 947 "Randomly defined CAN frame";
CM_ SG_ 947 checksum_41_8 "8 Bit checksum for protection of frame contents";
CM_ BO_ 1334 "Randomly defined CAN frame";
CM_ SG_ 1334 checksum_41_8 "8 Bit checksum for protection of frame contents";
CM_ BO_ 458 "Randomly defined CAN frame";
CM_ SG_ 458 checksum_1_8 "8 Bit checksum for protection of frame contents";
CM_ BO_ 915 "Randomly defined CAN frame";
CM_ SG_ 915 checksum_25_8 "8 Bit checksum for protection of frame contents";
CM_ BO_ 349 "Randomly defined CAN frame";
CM_ SG_ 349 checksum_17_8 "8 Bit checksum for protection of frame contents";
CM_ BO_ 1 "Randomly defined CAN frame";
CM_ SG_ 1 checksum_1_8 "8 Bit checksum for protection of frame contents";
CM_ BO_ 435 "Randomly defined CAN frame";
CM_ SG_ 435 checksum_9_8 "8 Bit checksum for protection of frame contents";
CM_ BO_ 982 "Randomly defined CAN frame";
CM_ SG_ 982 checksum_1_8 "8 Bit checksum for protection of frame contents";
CM_ BO_ 263 "Randomly defined CAN frame";
CM_ SG_ 263 checksum_41_8 "8 Bit checksum for protection of frame contents";
BA_DEF_  "Author" STRING ;
BA_DEF_ BO_  "frameSendMode" ENUM  "regular","event","mixed";
BA_DEF_ BO_  "sendPeriod" INT 5 10000;
BA_DEF_ BO_  "crcStartValue" INT 1 255;
BA_DEF_ BO_  "eventMinDistance" INT 5 10000;
BA_DEF_ SG_  "initialValue" FLOAT -1e+38 1e+38;
BA_DEF_DEF_  "Author" "http://sourceforge.net/projects/comframe/";
BA_DEF_DEF_  "frameSendMode" "regular";
BA_DEF_DEF_  "sendPeriod" 10;
BA_DEF_DEF_  "crcStartValue" 1;
BA_DEF_DEF_  "eventMinDistance" 10;
BA_DEF_DEF_  "initialValue" 0;
BA_ "frameSendMode" BO_ 1706 2;
BA_ "sendPeriod" BO_ 1706 100;
BA_ "eventMinDistance" BO_ 1706 100;
BA_ "crcStartValue" BO_ 1706 202;
BA_ "initialValue" SG_ 1706 sig_2_29 0.000181218058;
BA_ "initialValue" SG_ 1706 sig_0_2 3;
BA_ "initialValue" SG_ 1706 sig_42_14 -1480;
BA_ "initialValue" SG_ 1706 sig_34_6 62;
BA_ "initialValue" SG_ 1706 sig_33_2 -1;
BA_ "sendPeriod" BO_ 1242 500;
BA_ "crcStartValue" BO_ 1242 122;
BA_ "initialValue" SG_ 1242 sig_4_10 -0.000156;
BA_ "initialValue" SG_ 1242 sig_7_3 -1;
BA_ "initialValue" SG_ 1242 sig_18_12 -2.4672776602;
BA_ "initialValue" SG_ 1242 sig_17_4 -3;
BA_ "initialValue" SG_ 1242 sig_40_10 0.044122776602;
BA_ "initialValue" SG_ 1242 sig_50_1 1;
BA_ "sendPeriod" BO_ 774 1000;
BA_ "crcStartValue" BO_ 774 208;
BA_ "initialValue" SG_ 774 sig_27_13 -0.098;
BA_ "initialValue" SG_ 774 sig_9_8 -0.0003;
BA_ "initialValue" SG_ 774 sig_12_6 -32;
BA_ "initialValue" SG_ 774 sig_11_2 1;
BA_ "initialValue" SG_ 774 sig_24_3 6;
BA_ "initialValue" SG_ 774 sig_40_7 0.74622776602;
BA_ "crcStartValue" BO_ 2147485692 86;
BA_ "initialValue" SG_ 2147485692 sig_0_14 1.7912776602e-05;
BA_ "initialValue" SG_ 2147485692 sig_15_2 1;
BA_ "initialValue" SG_ 2147485692 sig_31_2 -2;
BA_ "initialValue" SG_ 2147485692 sig_24_1 1;
BA_ "frameSendMode" BO_ 1907 2;
BA_ "sendPeriod" BO_ 1907 100;
BA_ "eventMinDistance" BO_ 1907 100;
BA_ "crcStartValue" BO_ 1907 229;
BA_ "initialValue" SG_ 1907 sig_31_1 1;
BA_ "initialValue" SG_ 1907 sig_15_16 -45.199776602;
BA_ "initialValue" SG_ 1907 sig_25_24 571.91316602;
BA_ "initialValue" SG_ 1907 sig_30_5 -2;
BA_ "sendPeriod" BO_ 594 50;
BA_ "crcStartValue" BO_ 594 226;
BA_ "initialValue" SG_ 594 sig_5_25 6821.58;
BA_ "initialValue" SG_ 594 sig_1_4 6.1622776602;
BA_ "initialValue" SG_ 594 sig_0_1 1;
BA_ "initialValue" SG_ 594 sig_30_2 -1;
BA_ "initialValue" SG_ 594 sig_47_16 -0.0021182;
BA_ "sendPeriod" BO_ 1049 5;
BA_ "crcStartValue" BO_ 1049 9;
BA_ "initialValue" SG_ 1049 sig_3_14 6.8572776602;
BA_ "initialValue" SG_ 1049 sig_7_4 6;
BA_ "initialValue" SG_ 1049 sig_16_6 -22;
BA_ "initialValue" SG_ 1049 sig_30_13 10177.27766;
BA_ "initialValue" SG_ 1049 sig_28_5 -12;
BA_ "initialValue" SG_ 1049 sig_29_1 1;
BA_ "initialValue" SG_ 1049 sig_43_5 1100;
BA_ "sendPeriod" BO_ 1207 25;
BA_ "crcStartValue" BO_ 1207 218;
BA_ "initialValue" SG_ 1207 sig_19_31 -0.0057972865;
BA_ "initialValue" SG_ 1207 sig_9_10 -34900;
BA_ "initialValue" SG_ 1207 sig_8_1 1;
BA_ "initialValue" SG_ 1207 sig_55_4 -2.1622776602e-06;
BA_ "sendPeriod" BO_ 902 10000;
BA_ "crcStartValue" BO_ 902 5;
BA_ "initialValue" SG_ 902 sig_10_13 2.9632776602e-06;
BA_ "initialValue" SG_ 902 sig_7_13 1022;
BA_ "initialValue" SG_ 902 sig_29_6 7.5622776602;
BA_ "initialValue" SG_ 902 sig_46_13 484.1;
BA_ "initialValue" SG_ 902 sig_61_6 37;
BA_ "sendPeriod" BO_ 1834 100;
BA_ "crcStartValue" BO_ 1834 218;
BA_ "initialValue" SG_ 1834 sig_7_16 8.563e-06;
BA_ "initialValue" SG_ 1834 sig_28_20 0.056710123398;
BA_ "initialValue" SG_ 1834 sig_29_3 5;
BA_ "initialValue" SG_ 1834 sig_40_1 1;
BA_ "sendPeriod" BO_ 609 1000;
BA_ "crcStartValue" BO_ 609 104;
BA_ "initialValue" SG_ 609 sig_22_5 1;
BA_ "initialValue" SG_ 609 sig_8_8 -760;
BA_ "initialValue" SG_ 609 sig_16_2 3;
BA_ "initialValue" SG_ 609 sig_23_16 6655;
BA_ "sendPeriod" BO_ 1367 100;
BA_ "crcStartValue" BO_ 1367 167;
BA_ "initialValue" SG_ 1367 sig_21_16 0.7184;
BA_ "initialValue" SG_ 1367 sig_8_1 1;
BA_ "initialValue" SG_ 1367 sig_15_6 3562.2776602;
BA_ "initialValue" SG_ 1367 sig_9_1 1;
BA_ "initialValue" SG_ 1367 sig_22_2 2;
BA_ "initialValue" SG_ 1367 sig_37_5 17;
BA_ "initialValue" SG_ 1367 sig_32_1 1;
BA_ "initialValue" SG_ 1367 sig_50_14 140.8;
BA_ "initialValue" SG_ 1367 sig_48_2 -1;
BA_ "sendPeriod" BO_ 1053 500;
BA_ "crcStartValue" BO_ 1053 3;
BA_ "initialValue" SG_ 1053 sig_8_10 486;
BA_ "initialValue" SG_ 1053 sig_1_6 6;
BA_ "initialValue" SG_ 1053 sig_7_1 1;
BA_ "initialValue" SG_ 1053 sig_39_15 2.617;
BA_ "sendPeriod" BO_ 1114 20;
BA_ "crcStartValue" BO_ 1114 142;
BA_ "initialValue" SG_ 1114 sig_6_16 -0.0029622;
BA_ "initialValue" SG_ 1114 sig_16_7 0.021;
BA_ "initialValue" SG_ 1114 sig_30_7 0.0069;
BA_ "initialValue" SG_ 1114 sig_46_11 1.377e-05;
BA_ "initialValue" SG_ 1114 sig_48_4 38377.223398;
BA_ "sendPeriod" BO_ 693 20;
BA_ "crcStartValue" BO_ 693 184;
BA_ "initialValue" SG_ 693 sig_1_12 0.000406;
BA_ "initialValue" SG_ 693 sig_2_6 -2.8622776602e-05;
BA_ "initialValue" SG_ 693 sig_16_5 10;
BA_ "initialValue" SG_ 693 sig_21_1 1;
BA_ "initialValue" SG_ 693 sig_31_12 382.1;
BA_ "initialValue" SG_ 693 sig_32_4 6000;
BA_ "initialValue" SG_ 693 sig_48_11 -591;
BA_ "initialValue" SG_ 693 sig_63_5 0.14;
BA_ "sendPeriod" BO_ 1143 500;
BA_ "crcStartValue" BO_ 1143 99;
BA_ "initialValue" SG_ 1143 sig_8_13 0.95942776602;
BA_ "initialValue" SG_ 1143 sig_25_13 -7.94e-07;
BA_ "initialValue" SG_ 1143 sig_23_2 1;
BA_ "initialValue" SG_ 1143 sig_24_1 1;
BA_ "initialValue" SG_ 1143 sig_39_2 1;
BA_ "sendPeriod" BO_ 667 500;
BA_ "crcStartValue" BO_ 667 226;
BA_ "initialValue" SG_ 667 sig_22_35 4035.8350088;
BA_ "initialValue" SG_ 667 sig_9_6 6.6622776602;
BA_ "initialValue" SG_ 667 sig_48_3 -3;
BA_ "sendPeriod" BO_ 453 1000;
BA_ "crcStartValue" BO_ 453 230;
BA_ "initialValue" SG_ 453 sig_19_10 3.6477223398e-05;
BA_ "initialValue" SG_ 453 sig_8_10 667;
BA_ "initialValue" SG_ 453 sig_31_3 -2;
BA_ "initialValue" SG_ 453 sig_36_11 0.01474772234;
BA_ "initialValue" SG_ 453 sig_32_3 -4;
BA_ "frameSendMode" BO_ 1294 2;
BA_ "sendPeriod" BO_ 1294 100;
BA_ "eventMinDistance" BO_ 1294 100;
BA_ "crcStartValue" BO_ 1294 185;
BA_ "initialValue" SG_ 1294 sig_6_15 133.85;
BA_ "initialValue" SG_ 1294 sig_25_14 162.2;
BA_ "initialValue" SG_ 1294 sig_39_1 1;
BA_ "initialValue" SG_ 1294 sig_43_7 0.0010377223398;
BA_ "initialValue" SG_ 1294 sig_41_7 3.4e-05;
BA_ "sendPeriod" BO_ 403 1000;
BA_ "crcStartValue" BO_ 403 92;
BA_ "initialValue" SG_ 403 sig_12_24 1.219657234e-05;
BA_ "initialValue" SG_ 403 sig_5_9 5.1e-06;
BA_ "initialValue" SG_ 403 sig_36_5 8;
BA_ "initialValue" SG_ 403 sig_48_9 -0.022522776602;
BA_ "initialValue" SG_ 403 sig_55_7 -21.622776602;
BA_ "sendPeriod" BO_ 1051 25;
BA_ "crcStartValue" BO_ 1051 97;
BA_ "initialValue" SG_ 1051 sig_12_5 25;
BA_ "initialValue" SG_ 1051 sig_6_9 9.8e-06;
BA_ "initialValue" SG_ 1051 sig_13_1 1;
BA_ "initialValue" SG_ 1051 sig_26_15 6821;
BA_ "initialValue" SG_ 1051 sig_24_1 1;
BA_ "initialValue" SG_ 1051 sig_41_7 0.0088622776602;
BA_ "sendPeriod" BO_ 1352 50;
BA_ "crcStartValue" BO_ 1352 133;
BA_ "initialValue" SG_ 1352 sig_6_10 0.000462;
BA_ "initialValue" SG_ 1352 sig_30_7 114;
BA_ "initialValue" SG_ 1352 sig_8_5 17;
BA_ "initialValue" SG_ 1352 sig_16_8 2.076227766;
BA_ "initialValue" SG_ 1352 sig_39_13 -0.00017442776602;
BA_ "initialValue" SG_ 1352 sig_40_3 2;
BA_ "frameSendMode" BO_ 1140 2;
BA_ "sendPeriod" BO_ 1140 1000;
BA_ "eventMinDistance" BO_ 1140 1000;
BA_ "crcStartValue" BO_ 1140 148;
BA_ "initialValue" SG_ 1140 sig_16_14 0.29242776602;
BA_ "initialValue" SG_ 1140 sig_3_11 957;
BA_ "initialValue" SG_ 1140 sig_40_16 -0.0021309;
BA_ "sendPeriod" BO_ 652 20;
BA_ "crcStartValue" BO_ 652 185;
BA_ "initialValue" SG_ 652 sig_10_2 2;
BA_ "initialValue" SG_ 652 sig_9_2 3;
BA_ "initialValue" SG_ 652 sig_34_11 0.0049522776602;
BA_ "initialValue" SG_ 652 sig_32_2 1;
BA_ "initialValue" SG_ 652 sig_47_3 1;
BA_ "sendPeriod" BO_ 1091 100;
BA_ "crcStartValue" BO_ 1091 58;
BA_ "initialValue" SG_ 1091 sig_4_3 1;
BA_ "initialValue" SG_ 1091 sig_28_18 -0.00075563223398;
BA_ "initialValue" SG_ 1091 sig_15_15 -7583;
BA_ "initialValue" SG_ 1091 sig_16_1 1;
BA_ "initialValue" SG_ 1091 sig_26_3 -4;
BA_ "initialValue" SG_ 1091 sig_47_2 -2;
BA_ "sendPeriod" BO_ 1715 50;
BA_ "crcStartValue" BO_ 1715 69;
BA_ "initialValue" SG_ 1715 sig_4_4 -111622.7766;
BA_ "initialValue" SG_ 1715 sig_1_9 294;
BA_ "initialValue" SG_ 1715 sig_8_5 0.00031622776602;
BA_ "initialValue" SG_ 1715 sig_16_1 1;
BA_ "initialValue" SG_ 1715 sig_32_14 -2818.2776602;
BA_ "crcStartValue" BO_ 766 167;
BA_ "initialValue" SG_ 766 sig_17_39 -17292.567562;
BA_ "sendPeriod" BO_ 131 1000;
BA_ "crcStartValue" BO_ 131 23;
BA_ "initialValue" SG_ 131 sig_19_14 2.714e-06;
BA_ "initialValue" SG_ 131 sig_7_16 1229;
BA_ "initialValue" SG_ 131 sig_23_4 -0.0083772233983;
BA_ "initialValue" SG_ 131 sig_37_6 -3;
BA_ "initialValue" SG_ 131 sig_52_11 231;
BA_ "initialValue" SG_ 131 sig_55_3 2;
BA_ "initialValue" SG_ 131 sig_53_2 1;
BA_ "crcStartValue" BO_ 1271 96;
BA_ "initialValue" SG_ 1271 sig_5_37 -3.2395251483;
BA_ "sendPeriod" BO_ 332 20;
BA_ "crcStartValue" BO_ 332 118;
BA_ "initialValue" SG_ 332 sig_3_7 2.9377223398e-06;
BA_ "initialValue" SG_ 332 sig_1_8 -0.00091622776602;
BA_ "initialValue" SG_ 332 sig_31_16 27447;
BA_ "frameSendMode" BO_ 602 2;
BA_ "sendPeriod" BO_ 602 10000;
BA_ "eventMinDistance" BO_ 602 100;
BA_ "crcStartValue" BO_ 602 40;
BA_ "initialValue" SG_ 602 sig_40_15 0.04502;
BA_ "initialValue" SG_ 602 sig_9_12 31.1;
BA_ "initialValue" SG_ 602 sig_8_1 1;
BA_ "initialValue" SG_ 602 sig_21_19 3.33573e-06;
BA_ "initialValue" SG_ 602 sig_55_1 1;
BA_ "sendPeriod" BO_ 833 100;
BA_ "crcStartValue" BO_ 833 63;
BA_ "initialValue" SG_ 833 sig_11_6 -17;
BA_ "initialValue" SG_ 833 sig_1_7 42;
BA_ "initialValue" SG_ 833 sig_14_3 -1;
BA_ "initialValue" SG_ 833 sig_15_1 1;
BA_ "initialValue" SG_ 833 sig_16_6 18;
BA_ "initialValue" SG_ 833 sig_30_15 63.647776602;
BA_ "initialValue" SG_ 833 sig_55_7 -11;
BA_ "sendPeriod" BO_ 1605 50;
BA_ "crcStartValue" BO_ 1605 81;
BA_ "initialValue" SG_ 1605 sig_7_13 5661;
BA_ "initialValue" SG_ 1605 sig_9_9 54;
BA_ "initialValue" SG_ 1605 sig_10_1 1;
BA_ "initialValue" SG_ 1605 sig_39_13 2.547e-05;
BA_ "initialValue" SG_ 1605 sig_41_8 -70;
BA_ "initialValue" SG_ 1605 sig_49_2 1;
BA_ "sendPeriod" BO_ 514 25;
BA_ "crcStartValue" BO_ 514 140;
BA_ "initialValue" SG_ 514 sig_30_17 38573;
BA_ "initialValue" SG_ 514 sig_14_11 -305;
BA_ "initialValue" SG_ 514 sig_19_5 -6622.7766017;
BA_ "initialValue" SG_ 514 sig_40_14 85862.776602;
BA_ "initialValue" SG_ 514 sig_45_5 -0.09;
BA_ "initialValue" SG_ 514 sig_58_3 4;
BA_ "frameSendMode" BO_ 1731 2;
BA_ "sendPeriod" BO_ 1731 10000;
BA_ "eventMinDistance" BO_ 1731 1000;
BA_ "crcStartValue" BO_ 1731 176;
BA_ "initialValue" SG_ 1731 sig_7_7 -1.9622776602e-05;
BA_ "initialValue" SG_ 1731 sig_0_1 1;
BA_ "initialValue" SG_ 1731 sig_24_29 -5.3216565102e-06;
BA_ "initialValue" SG_ 1731 sig_22_10 282;
BA_ "initialValue" SG_ 1731 sig_59_4 0.2;
BA_ "sendPeriod" BO_ 1529 10000;
BA_ "crcStartValue" BO_ 1529 80;
BA_ "initialValue" SG_ 1529 sig_6_6 8;
BA_ "initialValue" SG_ 1529 sig_43_1 1;
BA_ "initialValue" SG_ 1529 sig_16_10 68.022776602;
BA_ "initialValue" SG_ 1529 sig_17_7 26;
BA_ "initialValue" SG_ 1529 sig_35_7 0.00032377223398;
BA_ "initialValue" SG_ 1529 sig_42_10 7.5e-05;
BA_ "sendPeriod" BO_ 417 50;
BA_ "crcStartValue" BO_ 417 189;
BA_ "initialValue" SG_ 417 sig_7_8 -0.46227766017;
BA_ "initialValue" SG_ 417 sig_16_14 -113.17223398;
BA_ "initialValue" SG_ 417 sig_21_5 0.0017;
BA_ "initialValue" SG_ 417 sig_34_9 267;
BA_ "initialValue" SG_ 417 sig_41_2 2;
BA_ "frameSendMode" BO_ 808 2;
BA_ "sendPeriod" BO_ 808 1000;
BA_ "eventMinDistance" BO_ 808 100;
BA_ "crcStartValue" BO_ 808 32;
BA_ "initialValue" SG_ 808 sig_2_11 727;
BA_ "initialValue" SG_ 808 sig_0_2 2;
BA_ "initialValue" SG_ 808 sig_28_15 16.312776602;
BA_ "initialValue" SG_ 808 sig_24_3 -3;
BA_ "initialValue" SG_ 808 sig_43_5 25;
BA_ "sendPeriod" BO_ 1181 25;
BA_ "crcStartValue" BO_ 1181 213;
BA_ "initialValue" SG_ 1181 sig_10_19 -0.0022827976602;
BA_ "initialValue" SG_ 1181 sig_32_13 4883;
BA_ "initialValue" SG_ 1181 sig_47_3 3;
BA_ "sendPeriod" BO_ 1725 100;
BA_ "crcStartValue" BO_ 1725 82;
BA_ "initialValue" SG_ 1725 sig_7_8 128377.2234;
BA_ "initialValue" SG_ 1725 sig_5_7 0.0032377223398;
BA_ "initialValue" SG_ 1725 sig_17_7 8.2e-06;
BA_ "initialValue" SG_ 1725 sig_35_12 12190;
BA_ "initialValue" SG_ 1725 sig_36_4 83.772233983;
BA_ "sendPeriod" BO_ 208 5;
BA_ "crcStartValue" BO_ 208 104;
BA_ "initialValue" SG_ 208 sig_7_8 -0.88;
BA_ "initialValue" SG_ 208 sig_24_13 3.311;
BA_ "initialValue" SG_ 208 sig_39_2 2;
BA_ "initialValue" SG_ 208 sig_47_8 4400;
BA_ "sendPeriod" BO_ 1246 10000;
BA_ "crcStartValue" BO_ 1246 5;
BA_ "initialValue" SG_ 1246 sig_7_8 0.096622776602;
BA_ "initialValue" SG_ 1246 sig_24_15 -7394;
BA_ "initialValue" SG_ 1246 sig_22_5 40.622776602;
BA_ "initialValue" SG_ 1246 sig_17_2 -2;
BA_ "sendPeriod" BO_ 1423 100;
BA_ "crcStartValue" BO_ 1423 91;
BA_ "initialValue" SG_ 1423 sig_1_8 159;
BA_ "initialValue" SG_ 1423 sig_0_1 1;
BA_ "initialValue" SG_ 1423 sig_10_4 7.1622776602e-06;
BA_ "initialValue" SG_ 1423 sig_14_1 1;
BA_ "initialValue" SG_ 1423 sig_26_13 -9067.2233983;
BA_ "frameSendMode" BO_ 2047 2;
BA_ "sendPeriod" BO_ 2047 50;
BA_ "eventMinDistance" BO_ 2047 50;
BA_ "crcStartValue" BO_ 2047 189;
BA_ "initialValue" SG_ 2047 sig_22_23 -0.025435246602;
BA_ "initialValue" SG_ 2047 sig_5_15 0.0028456776602;
BA_ "initialValue" SG_ 2047 sig_3_3 -1;
BA_ "initialValue" SG_ 2047 sig_0_1 1;
BA_ "initialValue" SG_ 2047 sig_4_1 1;
BA_ "initialValue" SG_ 2047 sig_20_2 1;
BA_ "initialValue" SG_ 2047 sig_54_2 2;
BA_ "sendPeriod" BO_ 846 50;
BA_ "crcStartValue" BO_ 846 193;
BA_ "initialValue" SG_ 846 sig_2_15 22723;
BA_ "initialValue" SG_ 846 sig_23_5 0.021622776602;
BA_ "initialValue" SG_ 846 sig_17_1 1;
BA_ "initialValue" SG_ 846 sig_25_7 16;
BA_ "initialValue" SG_ 846 sig_24_1 1;
BA_ "initialValue" SG_ 846 sig_47_15 -0.00037067776602;
BA_ "frameSendMode" BO_ 1764 2;
BA_ "sendPeriod" BO_ 1764 10000;
BA_ "eventMinDistance" BO_ 1764 1000;
BA_ "crcStartValue" BO_ 1764 34;
BA_ "initialValue" SG_ 1764 sig_21_14 -0.0024842776602;
BA_ "initialValue" SG_ 1764 sig_7_16 718;
BA_ "initialValue" SG_ 1764 sig_23_2 2;
BA_ "initialValue" SG_ 1764 sig_47_13 -3759;
BA_ "initialValue" SG_ 1764 sig_50_2 2;
BA_ "initialValue" SG_ 1764 sig_48_1 1;
BA_ "frameSendMode" BO_ 1412 1;
BA_ "eventMinDistance" BO_ 1412 500;
BA_ "crcStartValue" BO_ 1412 183;
BA_ "initialValue" SG_ 1412 sig_10_8 0.00095;
BA_ "initialValue" SG_ 1412 sig_8_2 1;
BA_ "initialValue" SG_ 1412 sig_23_6 0.00041;
BA_ "initialValue" SG_ 1412 sig_27_8 -0.013622776602;
BA_ "initialValue" SG_ 1412 sig_25_2 2;
BA_ "initialValue" SG_ 1412 sig_36_2 1;
BA_ "frameSendMode" BO_ 1445 2;
BA_ "sendPeriod" BO_ 1445 1000;
BA_ "eventMinDistance" BO_ 1445 50;
BA_ "crcStartValue" BO_ 1445 211;
BA_ "initialValue" SG_ 1445 sig_10_9 506;
BA_ "initialValue" SG_ 1445 sig_0_8 -1.08e-05;
BA_ "initialValue" SG_ 1445 sig_15_5 3000;
BA_ "initialValue" SG_ 1445 sig_29_15 -6.87e-05;
BA_ "initialValue" SG_ 1445 sig_17_2 3;
BA_ "initialValue" SG_ 1445 sig_46_5 22;
BA_ "initialValue" SG_ 1445 sig_56_7 24377.223398;
BA_ "initialValue" SG_ 1445 sig_63_1 1;
BA_ "sendPeriod" BO_ 590 10000;
BA_ "crcStartValue" BO_ 590 47;
BA_ "initialValue" SG_ 590 sig_5_15 10445;
BA_ "initialValue" SG_ 590 sig_17_4 837.72233983;
BA_ "initialValue" SG_ 590 sig_22_2 1;
BA_ "initialValue" SG_ 590 sig_30_7 -4862.2776602;
BA_ "initialValue" SG_ 590 sig_40_16 634.47766017;
BA_ "frameSendMode" BO_ 442 2;
BA_ "sendPeriod" BO_ 442 1000;
BA_ "eventMinDistance" BO_ 442 1000;
BA_ "crcStartValue" BO_ 442 207;
BA_ "initialValue" SG_ 442 sig_1_12 143;
BA_ "initialValue" SG_ 442 sig_3_4 13;
BA_ "initialValue" SG_ 442 sig_16_1 1;
BA_ "initialValue" SG_ 442 sig_29_6 4000;
BA_ "initialValue" SG_ 442 sig_46_7 3.9622776602;
BA_ "initialValue" SG_ 442 sig_45_9 171;
BA_ "sendPeriod" BO_ 672 25;
BA_ "crcStartValue" BO_ 672 158;
BA_ "initialValue" SG_ 672 sig_37_16 -3347;
BA_ "initialValue" SG_ 672 sig_10_6 536.22776602;
BA_ "initialValue" SG_ 672 sig_0_8 -2.7622776602;
BA_ "initialValue" SG_ 672 sig_15_5 4362.2776602;
BA_ "initialValue" SG_ 672 sig_16_7 23;
BA_ "initialValue" SG_ 672 sig_25_2 1;
BA_ "initialValue" SG_ 672 sig_32_5 27;
BA_ "sendPeriod" BO_ 1419 5;
BA_ "crcStartValue" BO_ 1419 155;
BA_ "initialValue" SG_ 1419 sig_8_8 69;
BA_ "initialValue" SG_ 1419 sig_0_7 -35;
BA_ "initialValue" SG_ 1419 sig_7_1 1;
BA_ "initialValue" SG_ 1419 sig_23_7 0.0038622776602;
BA_ "initialValue" SG_ 1419 sig_32_4 1.1e-05;
BA_ "sendPeriod" BO_ 2147483648 50;
BA_ "crcStartValue" BO_ 2147483648 38;
BA_ "initialValue" SG_ 2147483648 sig_24_17 -0.01331;
BA_ "initialValue" SG_ 2147483648 sig_18_8 0.0172;
BA_ "initialValue" SG_ 2147483648 sig_15_9 616.22776602;
BA_ "initialValue" SG_ 2147483648 sig_22_4 14;
BA_ "initialValue" SG_ 2147483648 sig_49_4 -8;
BA_ "initialValue" SG_ 2147483648 sig_53_3 -3;
BA_ "sendPeriod" BO_ 1630 50;
BA_ "crcStartValue" BO_ 1630 176;
BA_ "initialValue" SG_ 1630 sig_40_7 82;
BA_ "initialValue" SG_ 1630 sig_6_15 605.43776602;
BA_ "initialValue" SG_ 1630 sig_7_1 1;
BA_ "initialValue" SG_ 1630 sig_16_14 3551;
BA_ "initialValue" SG_ 1630 sig_47_1 1;
BA_ "sendPeriod" BO_ 718 5;
BA_ "crcStartValue" BO_ 718 107;
BA_ "initialValue" SG_ 718 sig_7_10 44.077223398;
BA_ "initialValue" SG_ 718 sig_10_4 2;
BA_ "initialValue" SG_ 718 sig_32_17 16241;
BA_ "initialValue" SG_ 718 sig_24_8 44;
BA_ "initialValue" SG_ 718 sig_33_6 -6.0622776602;
BA_ "sendPeriod" BO_ 1042 25;
BA_ "crcStartValue" BO_ 1042 254;
BA_ "initialValue" SG_ 1042 sig_10_21 0.073913023398;
BA_ "initialValue" SG_ 1042 sig_8_2 2;
BA_ "initialValue" SG_ 1042 sig_35_12 900;
BA_ "initialValue" SG_ 1042 sig_47_7 0.0001196227766;
BA_ "initialValue" SG_ 1042 sig_54_2 -2;
BA_ "frameSendMode" BO_ 2147485695 2;
BA_ "sendPeriod" BO_ 2147485695 500;
BA_ "eventMinDistance" BO_ 2147485695 500;
BA_ "crcStartValue" BO_ 2147485695 233;
BA_ "initialValue" SG_ 2147485695 sig_7_17 0.00044883;
BA_ "initialValue" SG_ 2147485695 sig_0_7 5.7377223398;
BA_ "initialValue" SG_ 2147485695 sig_24_8 2546.227766;
BA_ "initialValue" SG_ 2147485695 sig_40_15 0.1026;
BA_ "initialValue" SG_ 2147485695 sig_56_8 0.17;
BA_ "frameSendMode" BO_ 1473 2;
BA_ "sendPeriod" BO_ 1473 1000;
BA_ "eventMinDistance" BO_ 1473 50;
BA_ "crcStartValue" BO_ 1473 87;
BA_ "initialValue" SG_ 1473 sig_3_9 -2.3e-05;
BA_ "initialValue" SG_ 1473 sig_4_7 52;
BA_ "initialValue" SG_ 1473 sig_24_16 5.2782776602;
BA_ "initialValue" SG_ 1473 sig_47_16 5.9869776602e-05;
BA_ "sendPeriod" BO_ 1033 25;
BA_ "crcStartValue" BO_ 1033 217;
BA_ "initialValue" SG_ 1033 sig_0_8 -6.6622776602;
BA_ "initialValue" SG_ 1033 sig_17_9 161;
BA_ "initialValue" SG_ 1033 sig_20_4 0.0031622776602;
BA_ "initialValue" SG_ 1033 sig_32_4 13;
BA_ "frameSendMode" BO_ 803 2;
BA_ "sendPeriod" BO_ 803 100;
BA_ "eventMinDistance" BO_ 803 50;
BA_ "crcStartValue" BO_ 803 133;
BA_ "initialValue" SG_ 803 sig_1_10 1214.227766;
BA_ "initialValue" SG_ 803 sig_0_6 0.033622776602;
BA_ "initialValue" SG_ 803 sig_24_8 -85;
BA_ "sendPeriod" BO_ 779 25;
BA_ "crcStartValue" BO_ 779 215;
BA_ "initialValue" SG_ 779 sig_3_11 -0.80222776602;
BA_ "initialValue" SG_ 779 sig_4_5 -1.7622776602e-06;
BA_ "initialValue" SG_ 779 sig_24_12 1956;
BA_ "initialValue" SG_ 779 sig_29_3 3;
BA_ "initialValue" SG_ 779 sig_30_1 1;
BA_ "initialValue" SG_ 779 sig_40_4 200;
BA_ "initialValue" SG_ 779 sig_55_8 2637.7223398;
BA_ "frameSendMode" BO_ 106 2;
BA_ "sendPeriod" BO_ 106 1000;
BA_ "eventMinDistance" BO_ 106 500;
BA_ "crcStartValue" BO_ 106 101;
BA_ "initialValue" SG_ 106 sig_7_11 218.0227766;
BA_ "initialValue" SG_ 106 sig_8_5 -0.0013;
BA_ "initialValue" SG_ 106 sig_29_14 64597.223398;
BA_ "initialValue" SG_ 106 sig_30_2 -2;
BA_ "sendPeriod" BO_ 905 500;
BA_ "crcStartValue" BO_ 905 13;
BA_ "initialValue" SG_ 905 sig_2_14 0.0001041272234;
BA_ "initialValue" SG_ 905 sig_0_2 2;
BA_ "initialValue" SG_ 905 sig_47_13 1326.2776602;
BA_ "initialValue" SG_ 905 sig_27_5 2;
BA_ "initialValue" SG_ 905 sig_31_8 68;
BA_ "initialValue" SG_ 905 sig_28_3 4;
BA_ "initialValue" SG_ 905 sig_48_3 2;
BA_ "initialValue" SG_ 905 sig_58_6 -0.3;
BA_ "initialValue" SG_ 905 sig_56_2 1;
BA_ "crcStartValue" BO_ 877 118;
BA_ "initialValue" SG_ 877 sig_7_7 -2337.7223398;
BA_ "initialValue" SG_ 877 sig_0_1 1;
BA_ "initialValue" SG_ 877 sig_20_7 8.7622776602e-05;
BA_ "initialValue" SG_ 877 sig_21_9 2.5;
BA_ "sendPeriod" BO_ 489 100;
BA_ "crcStartValue" BO_ 489 52;
BA_ "initialValue" SG_ 489 sig_5_6 2.9e-05;
BA_ "initialValue" SG_ 489 sig_0_5 0.0004;
BA_ "initialValue" SG_ 489 sig_11_20 93651.176602;
BA_ "initialValue" SG_ 489 sig_33_7 88622.776602;
BA_ "initialValue" SG_ 489 sig_52_2 1;
BA_ "initialValue" SG_ 489 sig_54_2 2;
BA_ "sendPeriod" BO_ 1758 25;
BA_ "crcStartValue" BO_ 1758 11;
BA_ "initialValue" SG_ 1758 sig_6_16 22179;
BA_ "initialValue" SG_ 1758 sig_7_1 1;
BA_ "initialValue" SG_ 1758 sig_16_7 -88622.776602;
BA_ "initialValue" SG_ 1758 sig_39_8 4.6227766017;
BA_ "sendPeriod" BO_ 0 25;
BA_ "crcStartValue" BO_ 0 24;
BA_ "initialValue" SG_ 0 sig_11_13 0.00015267223398;
BA_ "initialValue" SG_ 0 sig_8_1 1;
BA_ "initialValue" SG_ 0 sig_30_24 9.9114546602e-05;
BA_ "initialValue" SG_ 0 sig_54_7 -93.622776602;
BA_ "sendPeriod" BO_ 1324 500;
BA_ "crcStartValue" BO_ 1324 172;
BA_ "initialValue" SG_ 1324 sig_7_5 0.005;
BA_ "sendPeriod" BO_ 1885 100;
BA_ "crcStartValue" BO_ 1885 12;
BA_ "initialValue" SG_ 1885 sig_13_13 696;
BA_ "initialValue" SG_ 1885 sig_15_2 -1;
BA_ "initialValue" SG_ 1885 sig_31_8 166;
BA_ "initialValue" SG_ 1885 sig_16_1 1;
BA_ "frameSendMode" BO_ 1415 2;
BA_ "sendPeriod" BO_ 1415 1000;
BA_ "eventMinDistance" BO_ 1415 100;
BA_ "crcStartValue" BO_ 1415 95;
BA_ "initialValue" SG_ 1415 sig_9_12 -874;
BA_ "initialValue" SG_ 1415 sig_0_4 12000;
BA_ "initialValue" SG_ 1415 sig_11_5 -0.00042622776602;
BA_ "initialValue" SG_ 1415 sig_10_1 1;
BA_ "initialValue" SG_ 1415 sig_29_5 5162.2776602;
BA_ "initialValue" SG_ 1415 sig_24_1 1;
BA_ "frameSendMode" BO_ 1252 2;
BA_ "sendPeriod" BO_ 1252 1000;
BA_ "eventMinDistance" BO_ 1252 500;
BA_ "crcStartValue" BO_ 1252 92;
BA_ "initialValue" SG_ 1252 sig_2_17 12377.776602;
BA_ "initialValue" SG_ 1252 sig_0_2 -1;
BA_ "initialValue" SG_ 1252 sig_23_5 14;
BA_ "initialValue" SG_ 1252 sig_39_7 0.075622776602;
BA_ "sendPeriod" BO_ 947 10000;
BA_ "crcStartValue" BO_ 947 204;
BA_ "initialValue" SG_ 947 sig_27_4 -0.31622776602;
BA_ "initialValue" SG_ 947 sig_7_2 -1;
BA_ "initialValue" SG_ 947 sig_17_6 0.0068622776602;
BA_ "initialValue" SG_ 947 sig_30_3 2;
BA_ "initialValue" SG_ 947 sig_16_2 1;
BA_ "initialValue" SG_ 947 sig_32_8 118;
BA_ "initialValue" SG_ 947 sig_49_15 10492;
BA_ "initialValue" SG_ 947 sig_48_1 1;
BA_ "sendPeriod" BO_ 1334 500;
BA_ "crcStartValue" BO_ 1334 7;
BA_ "initialValue" SG_ 1334 sig_30_10 396.22776602;
BA_ "initialValue" SG_ 1334 sig_10_9 105;
BA_ "initialValue" SG_ 1334 sig_6_3 3;
BA_ "initialValue" SG_ 1334 sig_1_3 1;
BA_ "initialValue" SG_ 1334 sig_7_1 1;
BA_ "initialValue" SG_ 1334 sig_23_5 -5;
BA_ "initialValue" SG_ 1334 sig_8_2 1;
BA_ "initialValue" SG_ 1334 sig_25_5 160;
BA_ "initialValue" SG_ 1334 sig_24_1 1;
BA_ "frameSendMode" BO_ 458 2;
BA_ "sendPeriod" BO_ 458 10000;
BA_ "eventMinDistance" BO_ 458 50;
BA_ "crcStartValue" BO_ 458 54;
BA_ "initialValue" SG_ 458 sig_17_31 142352.8659;
BA_ "initialValue" SG_ 458 sig_15_6 4262.2776602;
BA_ "initialValue" SG_ 458 sig_53_5 0.0055622776602;
BA_ "initialValue" SG_ 458 sig_55_1 1;
BA_ "frameSendMode" BO_ 915 2;
BA_ "sendPeriod" BO_ 915 100;
BA_ "eventMinDistance" BO_ 915 100;
BA_ "crcStartValue" BO_ 915 205;
BA_ "initialValue" SG_ 915 sig_1_12 0.0023612776602;
BA_ "initialValue" SG_ 915 sig_36_13 6.5452776602e-05;
BA_ "initialValue" SG_ 915 sig_39_2 1;
BA_ "initialValue" SG_ 915 sig_37_1 1;
BA_ "sendPeriod" BO_ 349 25;
BA_ "crcStartValue" BO_ 349 39;
BA_ "initialValue" SG_ 349 sig_3_13 -3.5582776602e-06;
BA_ "initialValue" SG_ 349 sig_2_3 1;
BA_ "initialValue" SG_ 349 sig_28_10 -0.00049922776602;
BA_ "initialValue" SG_ 349 sig_46_7 -35;
BA_ "initialValue" SG_ 349 sig_47_1 1;
BA_ "frameSendMode" BO_ 1 2;
BA_ "sendPeriod" BO_ 1 1000;
BA_ "eventMinDistance" BO_ 1 500;
BA_ "crcStartValue" BO_ 1 76;
BA_ "initialValue" SG_ 1 sig_13_13 -2810.2776602;
BA_ "initialValue" SG_ 1 sig_15_2 3;
BA_ "sendPeriod" BO_ 435 1000;
BA_ "crcStartValue" BO_ 435 248;
BA_ "initialValue" SG_ 435 sig_1_6 -2062.2776602;
BA_ "initialValue" SG_ 435 sig_0_1 1;
BA_ "initialValue" SG_ 435 sig_7_1 1;
BA_ "initialValue" SG_ 435 sig_27_19 2.56786e-06;
BA_ "initialValue" SG_ 435 sig_23_8 16100;
BA_ "initialValue" SG_ 435 sig_26_3 6;
BA_ "initialValue" SG_ 435 sig_46_2 -1;
BA_ "sendPeriod" BO_ 982 20;
BA_ "crcStartValue" BO_ 982 153;
BA_ "initialValue" SG_ 982 sig_13_23 5.2354896602e-05;
BA_ "initialValue" SG_ 982 sig_37_18 72840;
BA_ "initialValue" SG_ 982 sig_38_1 1;
BA_ "initialValue" SG_ 982 sig_51_3 -4;
BA_ "sendPeriod" BO_ 263 1000;
BA_ "crcStartValue" BO_ 263 70;
BA_ "initialValue" SG_ 263 sig_0_15 22539;
BA_ "initialValue" SG_ 263 sig_15_19 3.7431e-05;
BA_ "initialValue" SG_ 263 sig_38_3 5;
BA_ "initialValue" SG_ 263 sig_52_7 -260;
BA_ "initialValue" SG_ 263 sig_54_6 8.2622776602e-05;
BA_ "initialValue" SG_ 263 sig_53_1 1;
BA_ "initialValue" SG_ 263 sig_61_2 1;
